AUTOSAR XML (schema 00048)
package /ComponentTypes
  swc implementation Common_GateWay_Implementation: behavior=Common_GateWay_InternalBehavior
    code-descriptors:
      code Default: artifact-descriptors=autosar-engineering-object=category=SWSRC
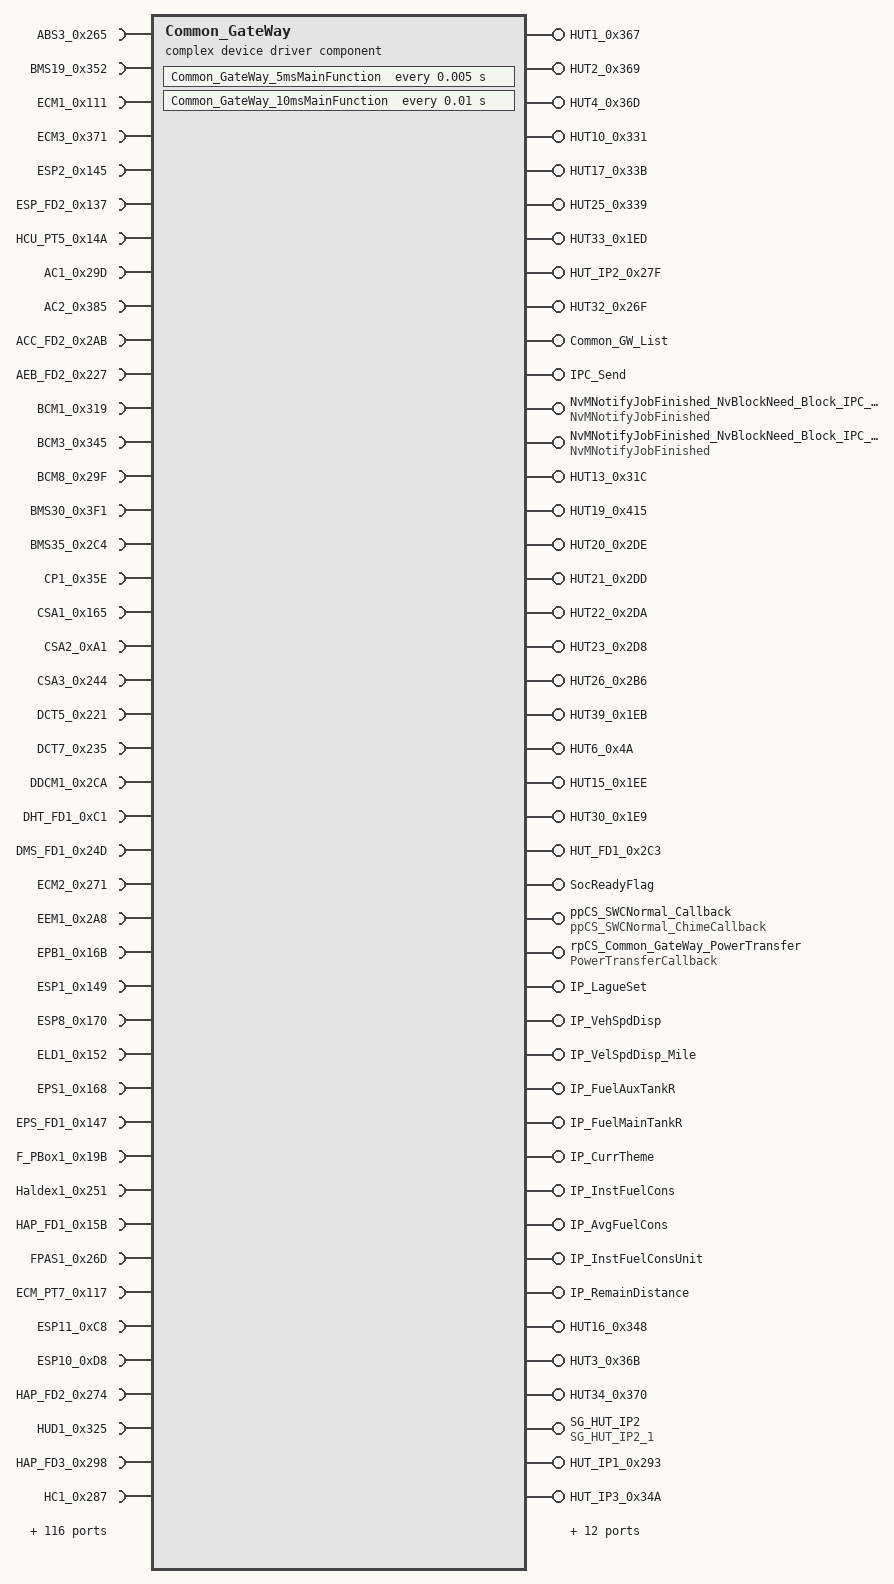
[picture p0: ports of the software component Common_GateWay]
  complex device driver sw component type Common_GateWay
    9 x require port:
      ABS3_0x265: nonqueued-receiver-com-spec{data-element=ABS3_0x265, alive-timeout=0.2, enable-update=true, filter=data-filter-type=ALWAYS, handle-never-received=true, init-value=16 x 0}, required-interface=ABS3_0x265
      BMS19_0x352: nonqueued-receiver-com-spec{data-element=BMS19_0x352, alive-timeout=5, enable-update=true, filter=data-filter-type=ALWAYS, handle-never-received=true, init-value=8 x 0}, required-interface=BMS19_0x352
      ECM1_0x111: nonqueued-receiver-com-spec{data-element=ECM1_0x111, alive-timeout=0.1, enable-update=true, filter=data-filter-type=ALWAYS, handle-never-received=true, init-value=8 x 0}, required-interface=ECM1_0x111
      ECM3_0x371: nonqueued-receiver-com-spec{data-element=ECM3_0x371, alive-timeout=1, enable-update=true, filter=data-filter-type=ALWAYS, handle-never-received=true, init-value=8 x 0}, required-interface=ECM3_0x371
      ESP2_0x145: nonqueued-receiver-com-spec{data-element=ESP2_0x145, alive-timeout=0.2, enable-update=true, filter=data-filter-type=ALWAYS, handle-never-received=true, init-value=16 x 0}, required-interface=ESP2_0x145
      ESP_FD2_0x137: nonqueued-receiver-com-spec{data-element=ESP_FD2_0x137, alive-timeout=0.2, enable-update=true, filter=data-filter-type=ALWAYS, handle-never-received=true, init-value=64 x 0}, required-interface=ESP_FD2_0x137
      HCU_PT5_0x14A: nonqueued-receiver-com-spec{data-element=HCU_PT5_0x14A, alive-timeout=0.2, enable-update=true, filter=data-filter-type=ALWAYS, handle-never-received=true, init-value=8 x 0}, required-interface=HCU_PT5_0x14A
      AC1_0x29D: nonqueued-receiver-com-spec{data-element=AC1_0x29D, alive-timeout=1, enable-update=true, filter=data-filter-type=ALWAYS, handle-never-received=true, init-value=8 x 0}, required-interface=AC1_0x29D
      AC2_0x385: nonqueued-receiver-com-spec{data-element=AC2_0x385, alive-timeout=1, filter=data-filter-type=ALWAYS, handle-never-received=true, init-value=8 x 0}, required-interface=AC2_0x385
    provide port HUT1_0x367: nonqueued-sender-com-spec{data-element=HUT1_0x367, init-value=8 x 0}, provided-interface=HUT1_0x367
    require port ACC_FD2_0x2AB: nonqueued-receiver-com-spec{data-element=ACC_FD2_0x2AB, alive-timeout=1, enable-update=true, filter=data-filter-type=ALWAYS, handle-never-received=true, init-value=64 x 0}, required-interface=ACC_FD2_0x2AB
    provide port HUT2_0x369: nonqueued-sender-com-spec{data-element=HUT2_0x369, init-value=8 x 0}, provided-interface=HUT2_0x369
    39 x require port:
      AEB_FD2_0x227: nonqueued-receiver-com-spec{data-element=AEB_FD2_0x227, alive-timeout=0.5, enable-update=true, filter=data-filter-type=ALWAYS, handle-never-received=true, init-value=64 x 0}, required-interface=AEB_FD2_0x227
      BCM1_0x319: nonqueued-receiver-com-spec{data-element=BCM1_0x319, alive-timeout=0.5, enable-update=true, filter=data-filter-type=ALWAYS, handle-never-received=true, init-value=16 x 0}, required-interface=BCM1_0x319
      BCM3_0x345: nonqueued-receiver-com-spec{data-element=BCM3_0x345, alive-timeout=0.5, enable-update=true, filter=data-filter-type=ALWAYS, handle-never-received=true, init-value=16 x 0}, required-interface=BCM3_0x345
      BCM8_0x29F: nonqueued-receiver-com-spec{data-element=BCM8_0x29F, alive-timeout=1, enable-update=true, filter=data-filter-type=ALWAYS, handle-never-received=true, init-value=8 x 0}, required-interface=BCM8_0x29F
      BMS30_0x3F1: nonqueued-receiver-com-spec{data-element=BMS30_0x3F1, alive-timeout=10, enable-update=true, filter=data-filter-type=ALWAYS, handle-never-received=true, init-value=8 x 0}, required-interface=BMS30_0x3F1
      BMS35_0x2C4: nonqueued-receiver-com-spec{data-element=BMS35_0x2C4, alive-timeout=1, enable-update=true, filter=data-filter-type=ALWAYS, handle-never-received=true, init-value=8 x 0}, required-interface=BMS35_0x2C4
      CP1_0x35E: nonqueued-receiver-com-spec{data-element=CP1_0x35E, alive-timeout=5, enable-update=true, filter=data-filter-type=ALWAYS, handle-never-received=true, init-value=8 x 0}, required-interface=CP1_0x35E
      CSA1_0x165: nonqueued-receiver-com-spec{data-element=CSA1_0x165, alive-timeout=0.2, enable-update=true, filter=data-filter-type=ALWAYS, handle-never-received=true, init-value=8 x 0}, required-interface=CSA1_0x165
      CSA2_0xA1: nonqueued-receiver-com-spec{data-element=CSA2_0xA1, alive-timeout=0.1, enable-update=true, filter=data-filter-type=ALWAYS, handle-never-received=true, init-value=8 x 0}, required-interface=CSA2_0xA1
      CSA3_0x244: nonqueued-receiver-com-spec{data-element=CSA3_0x244, alive-timeout=0.5, enable-update=true, filter=data-filter-type=ALWAYS, handle-never-received=true, init-value=8 x 0}, required-interface=CSA3_0x244
      DCT5_0x221: nonqueued-receiver-com-spec{data-element=DCT5_0x221, alive-timeout=0.2, enable-update=true, filter=data-filter-type=ALWAYS, handle-never-received=true, init-value=8 x 0}, required-interface=DCT5_0x221
      DCT7_0x235: nonqueued-receiver-com-spec{data-element=DCT7_0x235, alive-timeout=0.5, enable-update=true, filter=data-filter-type=ALWAYS, handle-never-received=true, init-value=16 x 0}, required-interface=DCT7_0x235
      DDCM1_0x2CA: nonqueued-receiver-com-spec{data-element=DDCM1_0x2CA, alive-timeout=1, enable-update=true, filter=data-filter-type=ALWAYS, handle-never-received=true, init-value=8 x 0}, required-interface=DDCM1_0x2CA
      DHT_FD1_0xC1: nonqueued-receiver-com-spec{data-element=DHT_FD1_0xC1, alive-timeout=0.1, enable-update=true, filter=data-filter-type=ALWAYS, handle-never-received=true, init-value=64 x 0}, required-interface=DHT_FD1_0xC1
      DMS_FD1_0x24D: nonqueued-receiver-com-spec{data-element=DMS_FD1_0x24D, alive-timeout=0.5, enable-update=true, filter=data-filter-type=ALWAYS, handle-never-received=true, init-value=64 x 0}, required-interface=DMS_FD1_0x24D
      ECM2_0x271: nonqueued-receiver-com-spec{data-element=ECM2_0x271, alive-timeout=0.2, enable-update=true, filter=data-filter-type=ALWAYS, handle-never-received=true, init-value=8 x 0}, required-interface=ECM2_0x271
      EEM1_0x2A8: nonqueued-receiver-com-spec{data-element=EEM1_0x2A8, alive-timeout=1, enable-update=true, filter=data-filter-type=ALWAYS, handle-never-received=true, init-value=8 x 0}, required-interface=EEM1_0x2A8
      EPB1_0x16B: nonqueued-receiver-com-spec{data-element=EPB1_0x16B, alive-timeout=0.2, enable-update=true, filter=data-filter-type=ALWAYS, handle-never-received=true, init-value=8 x 0}, required-interface=EPB1_0x16B
      ESP1_0x149: nonqueued-receiver-com-spec{data-element=ESP1_0x149, alive-timeout=0.2, enable-update=true, filter=data-filter-type=ALWAYS, handle-never-received=true, init-value=16 x 0}, required-interface=ESP1_0x149
      ESP8_0x170: nonqueued-receiver-com-spec{data-element=ESP8_0x170, alive-timeout=0.2, enable-update=true, filter=data-filter-type=ALWAYS, handle-never-received=true, init-value=8 x 0}, required-interface=ESP8_0x170
      ELD1_0x152: nonqueued-receiver-com-spec{data-element=ELD1_0x152, alive-timeout=0.2, enable-update=true, filter=data-filter-type=ALWAYS, handle-never-received=true, init-value=8 x 0}, required-interface=ELD1_0x152
      EPS1_0x168: nonqueued-receiver-com-spec{data-element=EPS1_0x168, alive-timeout=0.2, enable-update=true, filter=data-filter-type=ALWAYS, handle-never-received=true, init-value=8 x 0}, required-interface=EPS1_0x168
      EPS_FD1_0x147: nonqueued-receiver-com-spec{data-element=EPS_FD1_0x147, alive-timeout=0.2, enable-update=true, filter=data-filter-type=ALWAYS, handle-never-received=true, init-value=64 x 0}, required-interface=EPS_FD1_0x147
      F_PBox1_0x19B: nonqueued-receiver-com-spec{data-element=F_PBox1_0x19B, alive-timeout=0.5, enable-update=true, filter=data-filter-type=ALWAYS, handle-never-received=true, init-value=8 x 0}, required-interface=F_PBox1_0x19B
      Haldex1_0x251: nonqueued-receiver-com-spec{data-element=Haldex1_0x251, alive-timeout=0.2, enable-update=true, filter=data-filter-type=ALWAYS, handle-never-received=true, init-value=8 x 0}, required-interface=Haldex1_0x251
      HAP_FD1_0x15B: nonqueued-receiver-com-spec{data-element=HAP_FD1_0x15B, alive-timeout=0.2, enable-update=true, filter=data-filter-type=ALWAYS, handle-never-received=true, init-value=64 x 0}, required-interface=HAP_FD1_0x15B
      FPAS1_0x26D: nonqueued-receiver-com-spec{data-element=FPAS1_0x26D, alive-timeout=1, enable-update=true, filter=data-filter-type=ALWAYS, handle-never-received=true, init-value=8 x 0}, required-interface=FPAS1_0x26D
      ECM_PT7_0x117: nonqueued-receiver-com-spec{data-element=ECM_PT7_0x117, alive-timeout=0.2, enable-update=true, filter=data-filter-type=ALWAYS, handle-never-received=true, init-value=8 x 0}, required-interface=ECM_PT7_0x117
      ESP11_0xC8: nonqueued-receiver-com-spec{data-element=ESP11_0xC8, alive-timeout=0.1, enable-update=true, filter=data-filter-type=ALWAYS, handle-never-received=true, init-value=8 x 0}, required-interface=ESP11_0xC8
      ESP10_0xD8: nonqueued-receiver-com-spec{data-element=ESP10_0xD8, alive-timeout=0.1, enable-update=true, filter=data-filter-type=ALWAYS, handle-never-received=true, init-value=8 x 0}, required-interface=ESP10_0xD8
      HAP_FD2_0x274: nonqueued-receiver-com-spec{data-element=HAP_FD2_0x274, alive-timeout=0.5, enable-update=true, filter=data-filter-type=ALWAYS, handle-never-received=true, init-value=64 x 0}, required-interface=HAP_FD2_0x274
      HUD1_0x325: nonqueued-receiver-com-spec{data-element=HUD1_0x325, alive-timeout=2, enable-update=true, filter=data-filter-type=ALWAYS, handle-never-received=true, init-value=8 x 0}, required-interface=HUD1_0x325
      HAP_FD3_0x298: nonqueued-receiver-com-spec{data-element=HAP_FD3_0x298, alive-timeout=1, enable-update=true, filter=data-filter-type=ALWAYS, handle-never-received=true, init-value=64 x 0}, required-interface=HAP_FD3_0x298
      HC1_0x287: nonqueued-receiver-com-spec{data-element=HC1_0x287, alive-timeout=1, enable-update=true, filter=data-filter-type=ALWAYS, handle-never-received=true, init-value=8 x 0}, required-interface=HC1_0x287
      HCU_HC6_0x314: nonqueued-receiver-com-spec{data-element=HCU_HC6_0x314, alive-timeout=2, enable-update=true, filter=data-filter-type=ALWAYS, handle-never-received=true, init-value=8 x 0}, required-interface=HCU_HC6_0x314
      HCU_HC7_0x3C2: nonqueued-receiver-com-spec{data-element=HCU_HC7_0x3C2, alive-timeout=10, enable-update=true, filter=data-filter-type=ALWAYS, handle-never-received=true, init-value=8 x 0}, required-interface=HCU_HC7_0x3C2
      HCU_PT7_0x248: nonqueued-receiver-com-spec{data-element=HCU_PT7_0x248, alive-timeout=0.5, enable-update=true, filter=data-filter-type=ALWAYS, handle-never-received=true, init-value=8 x 0}, required-interface=HCU_PT7_0x248
      HCU_PT8_0x1C0: nonqueued-receiver-com-spec{data-element=HCU_PT8_0x1C0, alive-timeout=0.5, enable-update=true, filter=data-filter-type=ALWAYS, handle-never-received=true, init-value=8 x 0}, required-interface=HCU_PT8_0x1C0
      HCU_PT4_0x2FA: nonqueued-receiver-com-spec{data-element=HCU_PT4_0x2FA, alive-timeout=1, enable-update=true, filter=data-filter-type=ALWAYS, handle-never-received=true, init-value=8 x 0}, required-interface=HCU_PT4_0x2FA
    6 x provide port:
      HUT4_0x36D: nonqueued-sender-com-spec{data-element=HUT4_0x36D, init-value=8 x 0}, provided-interface=HUT4_0x36D
      HUT10_0x331: nonqueued-sender-com-spec{data-element=HUT10_0x331, init-value=8 x 0}, provided-interface=HUT10_0x331
      HUT17_0x33B: nonqueued-sender-com-spec{data-element=HUT17_0x33B, init-value=8 x 0}, provided-interface=HUT17_0x33B
      HUT25_0x339: nonqueued-sender-com-spec{data-element=HUT25_0x339, init-value=8 x 0}, provided-interface=HUT25_0x339
      HUT33_0x1ED: nonqueued-sender-com-spec{data-element=HUT33_0x1ED, init-value=8 x 0}, provided-interface=HUT33_0x1ED
      HUT_IP2_0x27F: nonqueued-sender-com-spec{data-element=HUT_IP2_0x27F, init-value=16 x 0}, provided-interface=HUT_IP2_0x27F
    18 x require port:
      IFC_FD3_0x2CF: nonqueued-receiver-com-spec{data-element=IFC_FD3_0x2CF, alive-timeout=1, enable-update=true, filter=data-filter-type=ALWAYS, handle-never-received=true, init-value=64 x 0}, required-interface=IFC_FD3_0x2CF
      PEPS2_0x295: nonqueued-receiver-com-spec{data-element=PEPS2_0x295, alive-timeout=0.5, enable-update=true, filter=data-filter-type=ALWAYS, handle-never-received=true, init-value=8 x 0}, required-interface=PEPS2_0x295
      PEPS4_0x302: nonqueued-receiver-com-spec{data-element=PEPS4_0x302, alive-timeout=2, enable-update=true, filter=data-filter-type=ALWAYS, handle-never-received=true, init-value=8 x 0}, required-interface=PEPS4_0x302
      RPAS1_0x26E: nonqueued-receiver-com-spec{data-element=RPAS1_0x26E, alive-timeout=1, enable-update=true, filter=data-filter-type=ALWAYS, handle-never-received=true, init-value=8 x 0}, required-interface=RPAS1_0x26E
      PDCM1_0x2CD: nonqueued-receiver-com-spec{data-element=PDCM1_0x2CD, alive-timeout=1, enable-update=true, filter=data-filter-type=ALWAYS, handle-never-received=true, init-value=8 x 0}, required-interface=PDCM1_0x2CD
      OBC1_0x316: nonqueued-receiver-com-spec{data-element=OBC1_0x316, alive-timeout=2, enable-update=true, filter=data-filter-type=ALWAYS, handle-never-received=true, init-value=8 x 0}, required-interface=OBC1_0x316
      OBC2_0x317: nonqueued-receiver-com-spec{data-element=OBC2_0x317, alive-timeout=2, enable-update=true, filter=data-filter-type=ALWAYS, handle-never-received=true, init-value=8 x 0}, required-interface=OBC2_0x317
      R_PBox1_0x19C: nonqueued-receiver-com-spec{data-element=R_PBox1_0x19C, alive-timeout=0.5, enable-update=true, filter=data-filter-type=ALWAYS, handle-never-received=true, init-value=16 x 0}, required-interface=R_PBox1_0x19C
      T_Box_FD1_0x33: nonqueued-receiver-com-spec{data-element=T_Box_FD1_0x33, enable-update=true, filter=data-filter-type=ALWAYS, handle-never-received=true, init-value=16 x 0}, required-interface=T_Box_FD1_0x33
      T_Box_FD3_0x3E9: nonqueued-receiver-com-spec{data-element=T_Box_FD3_0x3E9, alive-timeout=10, filter=data-filter-type=ALWAYS, init-value=16 x 0}, required-interface=T_Box_FD3_0x3E9
      RSDS_FD1_0x16F: nonqueued-receiver-com-spec{data-element=RSDS_FD1_0x16F, alive-timeout=0.2, enable-update=true, filter=data-filter-type=ALWAYS, handle-never-received=true, init-value=64 x 0}, required-interface=RSDS_FD1_0x16F
      SCM1_0x2D1: nonqueued-receiver-com-spec{data-element=SCM1_0x2D1, alive-timeout=1, enable-update=true, filter=data-filter-type=ALWAYS, handle-never-received=true, init-value=8 x 0}, required-interface=SCM1_0x2D1
      WPC1_0x2BA: nonqueued-receiver-com-spec{data-element=WPC1_0x2BA, alive-timeout=1, enable-update=true, filter=data-filter-type=ALWAYS, handle-never-received=true, init-value=8 x 0}, required-interface=WPC1_0x2BA
      TPMS1_0x341: nonqueued-receiver-com-spec{data-element=TPMS1_0x341, alive-timeout=5, filter=data-filter-type=ALWAYS, handle-never-received=true, init-value=16 x 0}, required-interface=TPMS1_0x341
      TPMS2_0x395: nonqueued-receiver-com-spec{data-element=TPMS2_0x395, alive-timeout=5, enable-update=true, filter=data-filter-type=ALWAYS, handle-never-received=true, init-value=16 x 0}, required-interface=TPMS2_0x395
      Trailer1_0x273: nonqueued-receiver-com-spec{data-element=Trailer1_0x273, alive-timeout=0.5, filter=data-filter-type=ALWAYS, init-value=8 x 0}, required-interface=Trailer1_0x273
      VSG1_0x2E1: nonqueued-receiver-com-spec{data-element=VSG1_0x2E1, alive-timeout=1, enable-update=true, filter=data-filter-type=ALWAYS, handle-never-received=true, init-value=8 x 0}, required-interface=VSG1_0x2E1
      ESCL2_0x303: nonqueued-receiver-com-spec{data-element=ESCL2_0x303, enable-update=true, filter=data-filter-type=ALWAYS, handle-never-received=true, init-value=8 x 0}, required-interface=ESCL2_0x303
    provide port HUT32_0x26F: nonqueued-sender-com-spec{data-element=HUT32_0x26F, init-value=8 x 0}, provided-interface=HUT32_0x26F
    provide port Common_GW_List: provided-com-specs=[{operation=Deinit, queue-length=1}, {operation=Int, queue-length=1}], provided-interface=Common_GW_List
    provide port IPC_Send: server-com-spec{operation=IPC_Send, queue-length=1}, provided-interface=IPC_Send
    10 x require port:
      BMS4_0xF1: nonqueued-receiver-com-spec{data-element=BMS4_0xF1, alive-timeout=0.1, enable-update=true, filter=data-filter-type=ALWAYS, handle-never-received=true, init-value=8 x 0}, required-interface=BMS4_0xF1
      ABM1_0x351: nonqueued-receiver-com-spec{data-element=ABM1_0x351, alive-timeout=5, enable-update=true, filter=data-filter-type=ALWAYS, handle-never-received=true, init-value=16 x 0}, required-interface=ABM1_0x351
      IFC_FD2_0x23D: nonqueued-receiver-com-spec{data-element=IFC_FD2_0x23D, alive-timeout=0.5, enable-update=true, filter=data-filter-type=ALWAYS, handle-never-received=true, init-value=64 x 0}, required-interface=IFC_FD2_0x23D
      IFC_FD5_0x19F: nonqueued-receiver-com-spec{data-element=IFC_FD5_0x19F, alive-timeout=0.5, enable-update=true, filter=data-filter-type=ALWAYS, handle-never-received=true, init-value=64 x 0}, required-interface=IFC_FD5_0x19F
      IFC_FD6_0x222: nonqueued-receiver-com-spec{data-element=IFC_FD6_0x222, alive-timeout=0.5, enable-update=true, filter=data-filter-type=ALWAYS, handle-never-received=true, init-value=64 x 0}, required-interface=IFC_FD6_0x222
      CR_FD1_0x15E: nonqueued-receiver-com-spec{data-element=CR_FD1_0x15E, alive-timeout=0.2, enable-update=true, filter=data-filter-type=ALWAYS, handle-never-received=true, init-value=64 x 0}, required-interface=CR_FD1_0x15E
      EOL_PartNumber_0xF187: nonqueued-receiver-com-spec{data-element=PartNumber_0xF187, filter=data-filter-type=ALWAYS, init-value=13 x 0}, required-interface=EOL_PartNumber_0xF187
      EOL_ReadHardVersion_0xF193: nonqueued-receiver-com-spec{data-element=ReadHardVersion_0xF193, filter=data-filter-type=ALWAYS, init-value=15 x 0}, required-interface=EOL_ReadHardVersion_0xF193
      EOL_ReadSerialNumber_ProductData_0xF18C: nonqueued-receiver-com-spec{data-element=ReadSerialNumber_ProductData_0xF18C, filter=data-filter-type=ALWAYS, init-value=20 x 0}, required-interface=EOL_ReadSerialNumber_ProductData_0xF18C
      EOL_VIPSoftwareVersion_0xFD01: nonqueued-receiver-com-spec{data-element=VIPSoftwareVersion_0xFD01, filter=data-filter-type=ALWAYS, init-value=[0, 0, 0, 0]}, required-interface=EOL_VIPSoftwareVersion_0xFD01
    provide port NvMNotifyJobFinished_NvBlockNeed_Block_IPC_CAN_Data: server-com-spec{operation=JobFinished, queue-length=1}, provided-interface=NvMNotifyJobFinished
    require port NvMService_AC3_Defs_NvBlockNeed_Block_IPC_CAN_Data: required-com-specs=[WriteBlock, RestoreBlockDefaults, ReadBlock, InvalidateNvBlock, GetErrorStatus, EraseBlock], required-interface=NvMService_AC3_Defs
    provide port NvMNotifyJobFinished_NvBlockNeed_Block_IPC_Config_Data: server-com-spec{operation=JobFinished, queue-length=1}, provided-interface=NvMNotifyJobFinished
    9 x require port:
      NvMService_AC3_Defs_NvBlockNeed_Block_IPC_Config_Data: required-com-specs=[WriteBlock, RestoreBlockDefaults, ReadBlock, InvalidateNvBlock, GetErrorStatus, EraseBlock], required-interface=NvMService_AC3_Defs
      AMP2_0x3E3: nonqueued-receiver-com-spec{data-element=AMP2_0x3E3, enable-update=true, filter=data-filter-type=ALWAYS, handle-never-received=true, init-value=16 x 0}, required-interface=AMP2_0x3E3
      AMP3_0x3E5: nonqueued-receiver-com-spec{data-element=AMP3_0x3E5, enable-update=true, filter=data-filter-type=ALWAYS, handle-never-received=true, init-value=8 x 0}, required-interface=AMP3_0x3E5
      BCM12_0x238: nonqueued-receiver-com-spec{data-element=BCM12_0x238, alive-timeout=0.5, enable-update=true, filter=data-filter-type=ALWAYS, handle-never-received=true, init-value=8 x 0}, required-interface=BCM12_0x238
      DSM1_0x2C1: nonqueued-receiver-com-spec{data-element=DSM1_0x2C1, alive-timeout=1, enable-update=true, filter=data-filter-type=ALWAYS, handle-never-received=true, init-value=8 x 0}, required-interface=DSM1_0x2C1
      GW_FD1_0x2BB: nonqueued-receiver-com-spec{data-element=GW_FD1_0x2BB, alive-timeout=1, enable-update=true, filter=data-filter-type=ALWAYS, handle-never-received=true, init-value=64 x 0}, required-interface=GW_FD1_0x2BB
      RPAS2_0x2ED: nonqueued-receiver-com-spec{data-element=RPAS2_0x2ED, alive-timeout=1, enable-update=true, filter=data-filter-type=ALWAYS, handle-never-received=true, init-value=8 x 0}, required-interface=RPAS2_0x2ED
      RSDS_FD2_0x30A: nonqueued-receiver-com-spec{data-element=RSDS_FD2_0x30A, alive-timeout=2, enable-update=true, filter=data-filter-type=ALWAYS, handle-never-received=true, init-value=64 x 0}, required-interface=RSDS_FD2_0x30A
      TMCU_FD3_0x3C9: nonqueued-receiver-com-spec{data-element=TMCU_FD3_0x3C9, alive-timeout=10, enable-update=true, filter=data-filter-type=ALWAYS, handle-never-received=true, init-value=8 x 0}, required-interface=TMCU_FD3_0x3C9
    12 x provide port:
      HUT13_0x31C: nonqueued-sender-com-spec{data-element=HUT13_0x31C, init-value=8 x 0}, provided-interface=HUT13_0x31C
      HUT19_0x415: nonqueued-sender-com-spec{data-element=HUT19_0x415, init-value=8 x 0}, provided-interface=HUT19_0x415
      HUT20_0x2DE: nonqueued-sender-com-spec{data-element=HUT20_0x2DE, init-value=8 x 0}, provided-interface=HUT20_0x2DE
      HUT21_0x2DD: nonqueued-sender-com-spec{data-element=HUT21_0x2DD, init-value=8 x 0}, provided-interface=HUT21_0x2DD
      HUT22_0x2DA: nonqueued-sender-com-spec{data-element=HUT22_0x2DA, init-value=8 x 0}, provided-interface=HUT22_0x2DA
      HUT23_0x2D8: nonqueued-sender-com-spec{data-element=HUT23_0x2D8, init-value=8 x 0}, provided-interface=HUT23_0x2D8
      HUT26_0x2B6: nonqueued-sender-com-spec{data-element=HUT26_0x2B6, init-value=8 x 0}, provided-interface=HUT26_0x2B6
      HUT39_0x1EB: nonqueued-sender-com-spec{data-element=HUT39_0x1EB, init-value=8 x 0}, provided-interface=HUT39_0x1EB
      HUT6_0x4A: nonqueued-sender-com-spec{data-element=HUT6_0x4A, init-value=8 x 0}, provided-interface=HUT6_0x4A
      HUT15_0x1EE: nonqueued-sender-com-spec{data-element=HUT15_0x1EE, init-value=16 x 0}, provided-interface=HUT15_0x1EE
      HUT30_0x1E9: nonqueued-sender-com-spec{data-element=HUT30_0x1E9, init-value=8 x 0}, provided-interface=HUT30_0x1E9
      HUT_FD1_0x2C3: nonqueued-sender-com-spec{data-element=HUT_FD1_0x2C3, init-value=64 x 0}, provided-interface=HUT_FD1_0x2C3
    4 x require port:
      ECM19_0x3B5: nonqueued-receiver-com-spec{data-element=ECM19_0x3B5, alive-timeout=1.2, filter=data-filter-type=ALWAYS, handle-never-received=true, init-value=8 x 0}, required-interface=ECM_VIN
      rpSR_SWCGateWay_Power_Out: nonqueued-receiver-com-spec{data-element=SystemStateOut, alive-timeout=1, filter=data-filter-type=ALWAYS, handle-never-received=true, init-value=constant-reference=PowerOutInit}, required-interface=tiSR_Power_Out
      rpSR_SWCGateWay_Fuel_Set_Module_Data: nonqueued-receiver-com-spec{data-element=Element, filter=data-filter-type=ALWAYS, init-value=fields=[Fuel_Fast_Fill_Status:0, Fuel_Fast_Fill_Status_Aux:0, 0, 0, Fuel_Level_Display_Percent:0, Fuel_Level_Display_Percent_Aux:0, Fuel_Level_Display_Segment:0, Fuel_Warning_Status_Aux:0, Fuel_Warning_Status:0, Fuel_Sensor_Error_Status_Aux:0, Fuel_Sensor_Error_Status:0, Fuel_Level_Display_Value:0, Fuel_Level_Calculate_Value_Aux:0, Fuel_Level_Calculate_Value:0, Fuel_Sensor_Raw_Value_A:0, Fuel_Level_Display_Value_Aux:0, Fuel_Sensor_Raw_Value_B:0, Fuel_Sensor_Switch:0]}, required-interface=tiSR_Fuel_Set_Module_Data
      rpSR_SWCGateWay_TC_Module_Output_Data: nonqueued-receiver-com-spec{data-element=Element, filter=data-filter-type=ALWAYS, init-value=fields=[u16AFE_1st_Display_Output_Data:0, u16AFE_2st_Display_Output_Data:0, u32AFE_1st_Fuel_Trip_Value:0, u32AFE_1st_Fuel_Consumption_Value:0, u32AFE_2st_Fuel_Trip_Value:0, u32AFE_2st_Fuel_Consumption_Value:0, u16IFE_Calculate_Output_Data:0, u16IFE_Display_Output_Data:0, u32IFE_Fuel_Trip_Value:0, u32IFE_Fuel_Consumption_Value:0, u32IFE_Fuel_Consumption_Can_Signal:0, u16AVS_1st_Display_Output_Data:0, u16AVS_2st_Display_Output_Data:0, u32AVS_1st_Driving_Time_Value:0, u32AVS_2st_Driving_Time_Value:0, u32AVS_1st_Fuel_Trip_Value:0, u32AVS_2st_Fuel_Trip_Value:0, u8DrivingTime_1st_Display_Hour:0, u8DrivingTime_2st_Display_Hour:0, u8DrivingTime_1st_Display_Minute:0, u8DrivingTime_2st_Display_Minute:0, u16DTE_Fuel_Tank_Volume:0, u16DTE_Fuel_Tank_Volume_Aux:0, u8DTE_Fuel_Stage_Consumption:0, u8DTE_Fuel_Stage_Consumption_Aux:0, u16DTE_Display_Output_Data:0, u16DTE_Display_Output_Data_Aux:0, u16DTE_Calculate_Output_Data:0, u16SFC_Output_Data:0, u8IFC_Poc_Update:0, u16IFC_Poc_Calculate_Value:0, u16SFC_For_Fuel_Output_Data:0, u16IFC_Poc_For_Fuel_Calculate_Rate:0, u16IFC_Poc_For_Fuel_Calculate_Rate_Aux:0]}, required-interface=tiSR_TC_Module_Output_Data
    provide port SocReadyFlag: nonqueued-sender-com-spec{data-element=Element, init-value=0}, provided-interface=SocReadyFlag
    provide port ppCS_SWCNormal_Callback: server-com-spec{operation=Operation, queue-length=1}, provided-interface=ppCS_SWCNormal_ChimeCallback
    7 x require port:
      rcCS_SWCNormal_ChimeCallback: client-com-spec=Operation, required-interface=tiCS_SWCNormal_ChimeCallback
      rcCS_SWCNormal_TTCallback: client-com-spec=Operation, required-interface=tiCS_SWCNormal_TTCallback
      rcCS_SWCNormal_WrnCallback: client-com-spec=Operation, required-interface=tiCS_SWCNormal_WrnCallback
      rpCS_AppClearDTCInfo: client-com-spec=AppClearDTCInfo, required-interface=PpCS_AppClearDTCInfo
      rpCS_AppReadDtcInfomation: client-com-spec=AppReadDtcInformation, required-interface=PpCS_AppReadDtcInfomation
      Rc_CanOutputViaGateway: required-interface=SafetyCanOutputViaNormal
        required-com-specs:
          data-element=RollingCounter_IP2, filter=data-filter-type=ALWAYS, init-value=0
          data-element=IP_VINcompr, filter=data-filter-type=ALWAYS, init-value=0
          data-element=IP_VehTotDistanceValid, filter=data-filter-type=ALWAYS, init-value=0
          data-element=IP_VehTotDistance, filter=data-filter-type=ALWAYS, init-value=16777215
          data-element=IP_PassSeatBeltWarnLmpFailSts, filter=data-filter-type=ALWAYS, init-value=0
          data-element=IP_VehSpdUnit, filter=data-filter-type=ALWAYS, init-value=0
          data-element=IP_FuelLvlInfo, filter=data-filter-type=ALWAYS, init-value=255
          data-element=IP_FuelLvlLowLmpSts, filter=data-filter-type=ALWAYS, init-value=0
          data-element=IP_Err, filter=data-filter-type=ALWAYS, init-value=0
          data-element=IP_EngOilPressLowLmpSts, filter=data-filter-type=ALWAYS, init-value=0
          data-element=IP_DrvSeatBeltWarnLmpFailSts, filter=data-filter-type=ALWAYS, init-value=0
          data-element=IP_BattChrgLmpSts, filter=data-filter-type=ALWAYS, init-value=0
          data-element=IP_ACCErr, filter=data-filter-type=ALWAYS, init-value=0
          data-element=IP_ABMWarnLmpFailrSts, filter=data-filter-type=ALWAYS, init-value=0
          data-element=dummy_HUT_IP2_0, filter=data-filter-type=ALWAYS, init-value=0
          data-element=CheckSum_IP2, filter=data-filter-type=ALWAYS, init-value=0
          data-element=IP_RemainDistance, filter=data-filter-type=ALWAYS, init-value=4095
          data-element=IP_InstFuelConsUnit, filter=data-filter-type=ALWAYS, init-value=0
          data-element=IP_AvgFuelCons, filter=data-filter-type=ALWAYS, init-value=4095
          data-element=IP_InstFuelCons, filter=data-filter-type=ALWAYS, init-value=16383
          data-element=IP_CurrTheme, filter=data-filter-type=ALWAYS, init-value=4
          data-element=IP_VehSpdDisp, filter=data-filter-type=ALWAYS, init-value=0
          data-element=IP_FuelMainTankR, filter=data-filter-type=ALWAYS, init-value=10
          data-element=IP_FuelAuxTankR, filter=data-filter-type=ALWAYS, init-value=10
          data-element=IP_VelSpdDisp_Mile, filter=data-filter-type=ALWAYS, init-value=0
          data-element=IP_LagueSet, filter=data-filter-type=ALWAYS, init-value=15
          data-element=IP_EBDFailSts, filter=data-filter-type=ALWAYS, init-value=0
      CNA_SignalSet: client-com-spec=Operation, required-interface=CNA_SignalSet
    provide port rpCS_Common_GateWay_PowerTransfer: provided-com-specs=[{operation=Standby2NomalCallback, queue-length=1}, {operation=Nomal2StandbyCallback, queue-length=1}], provided-interface=PowerTransferCallback
    require port rcCS_SWCNormal_HMIResetTC: client-com-spec=Callback, required-interface=tiCS_HMIResetTC
    require port rcCS_SWCNormal_ReceiveMenuSetting: client-com-spec=Callback, required-interface=tiCS_ReceiveMenuSetting
    10 x provide port:
      IP_LagueSet: nonqueued-sender-com-spec{data-element=IP_LagueSet, init-value=0}, provided-interface=IP_LagueSet
      IP_VehSpdDisp: nonqueued-sender-com-spec{data-element=IP_VehSpdDisp, init-value=0}, provided-interface=IP_VehSpdDisp
      IP_VelSpdDisp_Mile: nonqueued-sender-com-spec{data-element=IP_VelSpdDisp_Mile, init-value=0}, provided-interface=IP_VelSpdDisp_Mile
      IP_FuelAuxTankR: nonqueued-sender-com-spec{data-element=IP_FuelAuxTankR, init-value=0}, provided-interface=IP_FuelAuxTankR
      IP_FuelMainTankR: nonqueued-sender-com-spec{data-element=IP_FuelMainTankR, init-value=0}, provided-interface=IP_FuelMainTankR
      IP_CurrTheme: nonqueued-sender-com-spec{data-element=IP_CurrTheme, init-value=0}, provided-interface=IP_CurrTheme
      IP_InstFuelCons: nonqueued-sender-com-spec{data-element=IP_InstFuelCons, init-value=0}, provided-interface=IP_InstFuelCons
      IP_AvgFuelCons: nonqueued-sender-com-spec{data-element=IP_AvgFuelCons, init-value=0}, provided-interface=IP_AvgFuelCons
      IP_InstFuelConsUnit: nonqueued-sender-com-spec{data-element=IP_InstFuelConsUnit, init-value=0}, provided-interface=IP_InstFuelConsUnit
      IP_RemainDistance: nonqueued-sender-com-spec{data-element=IP_RemainDistance, init-value=0}, provided-interface=IP_RemainDistance
    5 x require port:
      ABS1_0x231: nonqueued-receiver-com-spec{data-element=ABS1_0x231, alive-timeout=0.2, enable-update=true, filter=data-filter-type=ALWAYS, handle-never-received=true, init-value=8 x 0}, required-interface=ABS1_0x231
      ABS2_0x246: nonqueued-receiver-com-spec{data-element=ABS2_0x246, alive-timeout=0.2, enable-update=true, filter=data-filter-type=ALWAYS, handle-never-received=true, init-value=8 x 0}, required-interface=ABS2_0x246
      ACC_FD3_0x2B4: nonqueued-receiver-com-spec{data-element=ACC_FD3_0x2B4, alive-timeout=1, enable-update=true, filter=data-filter-type=ALWAYS, handle-never-received=true, init-value=64 x 0}, required-interface=ACC_FD3_0x2B4
      BCM6_0x28C: nonqueued-receiver-com-spec{data-element=BCM6_0x28C, alive-timeout=1, enable-update=true, filter=data-filter-type=ALWAYS, handle-never-received=true, init-value=8 x 0}, required-interface=BCM6_0x28C
      PLG_1_0x2FE: nonqueued-receiver-com-spec{data-element=PLG_1_0x2FE, alive-timeout=1, enable-update=true, filter=data-filter-type=ALWAYS, handle-never-received=true, init-value=8 x 0}, required-interface=PLG_1_0x2FE
    4 x provide port:
      HUT16_0x348: nonqueued-sender-com-spec{data-element=HUT16_0x348, init-value=8 x 0}, provided-interface=HUT16_0x348
      HUT3_0x36B: nonqueued-sender-com-spec{data-element=HUT3_0x36B, init-value=8 x 0}, provided-interface=HUT3_0x36B
      HUT34_0x370: nonqueued-sender-com-spec{data-element=HUT34_0x370, init-value=8 x 0}, provided-interface=HUT34_0x370
      SG_HUT_IP2: nonqueued-sender-com-spec{data-element=SG_HUT_IP2, uses-end-to-end-protection=true, init-value=fields=[CheckSum_IP2:0, IP_ABMWarnLmpFailrSts:0, IP_ACCErr:0, IP_BattChrgLmpSts:0, IP_DrvSeatBeltWarnLmpFailSts:0, IP_EngOilPressLowLmpSts:0, IP_Err:0, IP_FuelLvlInfo:0, IP_FuelLvlLowLmpSts:0, IP_PassSeatBeltWarnLmpFailSts:0, IP_VehSpdUnit:0, IP_VehTotDistance:0, IP_VehTotDistanceValid:0, IP_VINcompr:0, RollingCounter_IP2:0]}, provided-interface=SG_HUT_IP2_1
    require port rpSR_SWCGateWay_DtcInfoForIPErrorStatus: nonqueued-receiver-com-spec{data-element=Element, filter=data-filter-type=ALWAYS, init-value=0}, required-interface=tiSR_DtcInfoForIPErrorStatus
    require port rpCS_SWCGateWay_GetVinNumber: client-com-spec=Operation, required-interface=tiCS_GetVinNumber
    provide port HUT_IP1_0x293: nonqueued-sender-com-spec{data-element=HUT_IP1_0x293, init-value=8 x 0}, provided-interface=HUT_IP1_0x293
    provide port HUT_IP3_0x34A: nonqueued-sender-com-spec{data-element=HUT_IP3_0x34A, init-value=16 x 0}, provided-interface=HUT_IP3_0x34A
    11 x require port:
      Rc_CanOutout_IP_EBDFailSts: nonqueued-receiver-com-spec{data-element=IP_EBDFailSts, filter=data-filter-type=ALWAYS, init-value=0}, required-interface=IP_EBDFailSts
      ComM_UserRequest: required-com-specs=[GetRequestedComMode, GetMaxComMode, GetCurrentComMode, RequestComMode], required-interface=ComM_UserRequest
      SG_ACC7_ACC_FD2: nonqueued-receiver-com-spec{data-element=SG_ACC7_ACC_FD2, uses-end-to-end-protection=true, alive-timeout=1, enable-update=true, handle-never-received=true, init-value=fields=[ACC_LeTargrtDection:0, ACC_LeTgtDx:0, ACC_LeTgtDy:0, ACC_LeTgtTyp:0, ACC_RiTargrtDetn:0, ACC_RiTgtDx:0, ACC_RiTgtDy:0, ACC_RiTgtTyp:0, Checksum_ACC7:0, dummy_ACC_FD2_19:0, dummy_ACC_FD2_20:0, Request_driveoff:0, RollingCounter_ACC7:0]}, required-interface=SG_ACC7_ACC_FD2
      Cconfig_KindBuffers_400Bytes: nonqueued-receiver-com-spec{data-element=CconfigKind_400Bytes, filter=data-filter-type=ALWAYS, init-value=400 x 0}, required-interface=Cconfig_KindBuffers_400Bytes
      rpCS_SWCGateWay_ReceiveSafetyGearCRC: client-com-spec=Callback, required-interface=tiCS_ReceiveSafetyGearCRC
      rpCS_SWCGateWay_ReceiveSafetyTTCRC: client-com-spec=Callback, required-interface=tiCS_ReceiveSafetyTTCRC
      rcCS_SWCGateWay_ReceiveSafetyGearCRC: client-com-spec=Callback, required-interface=tiCS_ReceiveSafetyGearCRC
      rcCS_SWCGateWay_ReceiveSafetyTTCRC: client-com-spec=Callback, required-interface=tiCS_ReceiveSafetyTTCRC
      rpCS_GetVehicleModeInfo: client-com-spec=Data, required-interface=piCS_GetVehicleModeInfo
      rpCS_GetCANMatrixVersionInfo: client-com-spec=Data, required-interface=piCS_GetCANMatrixVersionInfo
      piSR_E2ESwitchChangeTrigger: nonqueued-receiver-com-spec{data-element=Element, filter=data-filter-type=ALWAYS, init-value=0}, required-interface=piSR_E2ESwitchChangeTrigger
    provide port ppCS_SWCGateWay_IPC_TransmitSignal: server-com-spec{operation=Callback, queue-length=1}, provided-interface=tiCS_IPC_TransmitSignal
    provide port ppCS_SWCGateWay_IPC_Tx_E2E_CanMsg_HUT_IP2: server-com-spec{operation=Callback, queue-length=1}, provided-interface=tiCS_IPC_Tx_E2E_CanMsg_HUT_IP2
    require port DCT3_0xA6: nonqueued-receiver-com-spec{data-element=DCT3_0xA6, alive-timeout=0.1, enable-update=true, handle-never-received=true, init-value=8 x 0}, required-interface=DCT3_0xA6
    require port ECM11_0x2D3: nonqueued-receiver-com-spec{data-element=ECM11_0x2D3, alive-timeout=1, enable-update=true, handle-never-received=true, init-value=8 x 0}, required-interface=ECM11_0x2D3
    require port rpSR_SWCGateWay_MenuSetData: nonqueued-receiver-com-spec{data-element=Element, filter=data-filter-type=ALWAYS, init-value=fields=[NaviLimitSpeed:0, OverSpeedEnable:0, Language:0, ClusterTheme:0, OdometerUnit:0, TemperatureUnit:0, TirePressureUnit:0, TripComputerId:0, InteractiveCarId:0, DrivingModeMemorySwitch:0, TimeUnit:0, HighwayAssistSwitch:0, LaneChangeAssistSwitch:0, Cluster_Sunrise_Sunset_Mode:0, Cluster_Auto_Mode:0, DrvgModeMemReq:0, DrvingModReq_HUT:0, DataSyncFlag:0, AtmosphereLampLinkageSwt_Sts:0, SimSoundWaveLinkageSwt_Sts:0]}, required-interface=tiSR_MenuSetData
    provide port ppCS_SWCGateWay_IPC_API_SetEventTxSignalBuffer: server-com-spec{operation=Operation, queue-length=1}, provided-interface=tiCS_IPC_API_SetEventTxSignalBuffer
    require port rpCS_SWCSafety_TTCallback: client-com-spec=Operation, required-interface=tiCS_SWCSafety_TTCallback
    provide port SG_HUT32: nonqueued-sender-com-spec{data-element=SG_HUT32, uses-end-to-end-protection=true, init-value=fields=[CheckSum_HUT32:0, ContnPrkgReq:0, ContnPrkgReqValid:0, DetVideoLost:0, PrkgCtrlModReq:0, PrkgCtrlModReqValid:0, PrkStraightContinueReq_HUT:0, PrkStraightModSel_HUT:0, PrkStraightStrtReq_HUT:0, PrkStraightSts_HUT:0, PrkStraightSuspendOrFinishReq_HUT:0, PrkStraightSwtReq_HUT:0, PrkStraightVehStrtReq_HUT_Valid:0, RollingCounter_HUT32:0, ScrnOpSts:0, VolLampDispSts:0, XLvl:2047, YLvl:2047]}, provided-interface=SG_HUT32
    provide port ppCS_SWCGateWay_IPC_Tx_E2E_CanMsg_HUT32: server-com-spec{operation=CallBack, queue-length=1}, provided-interface=tiCS_IPC_Tx_E2E_CanMsg_HUT32
    6 x require port:
      IPC_DataSend_If: client-com-spec=Operation, required-interface=IPC_DataSend_If
      rpCS_SWCGateWay_E2ESwitchStatusRead: client-com-spec=Operation, required-interface=tiCS_E2EAndSecocCommonPort
      rpCS_SWCGateWay_E2ESwitchStatusWrite: client-com-spec=Operation, required-interface=tiCS_E2EAndSecocCommonPort
      rpCS_SWCGateWay_SecOcSwitchStatusRead: client-com-spec=Operation, required-interface=tiCS_E2EAndSecocCommonPort
      rpCS_SWCGateWay_SecOcSwitchStatusWrite: client-com-spec=Operation, required-interface=tiCS_E2EAndSecocCommonPort
      ACC_FD4_0x2B8: nonqueued-receiver-com-spec{data-element=ACC_FD4_0x2B8, alive-timeout=1, enable-update=true, filter=data-filter-type=ALWAYS, handle-never-received=true, init-value=64 x 0}, required-interface=ACC_FD4_0x2B8
    provide port ppSR_SWCGateWay_S2M_Information: provided-com-specs=[{data-element=TachoValue, init-value=0}, {data-element=SpeedValue, init-value=0}], provided-interface=tiSR_S2M_Information
    4 x require port:
      SG_ACC6_ACC_FD2: nonqueued-receiver-com-spec{data-element=SG_ACC6_ACC_FD2, uses-end-to-end-protection=true, alive-timeout=1, enable-update=true, filter=data-filter-type=ALWAYS, handle-never-received=true, init-value=fields=[ACC_EgoStatus:0, ACC_PotentialTgtDetn:0, ACC_PotentialTgtDx:0, ACC_PotentialTgtDy:0, ACC_PotentialTgtTyp:0, ACC_RlvTgtDetn:0, ACC_RlvTgtDx:0, ACC_RlvTgtDy:0, ACC_RlvTgtTyp:0, Checksum_ACC6:0, dummy_ACC_FD2_16:0, dummy_ACC_FD2_17:0, dummy_ACC_FD2_18:0, RollingCounter_ACC6:0]}, required-interface=SG_ACC6_ACC_FD2
      SG_ACC8_ACC_FD2: nonqueued-receiver-com-spec{data-element=SG_ACC8_ACC_FD2, uses-end-to-end-protection=true, alive-timeout=1, enable-update=true, handle-never-received=true, init-value=fields=[ADAS_DriverInloop_Monitor:0, Checksum_ACC8:0, HWA_InterSysInfoDisp:0, HWA_LaneChange:0, HWA_LaneChangeReq:0, HWA_ModDisp:0, HWA_warning:0, Longctrl_HCUTrqReq_DVR:0, RollingCounter_ACC8:0, dummy_ACC_FD2_11:0, dummy_ACC_FD2_12:0, dummy_ACC_FD2_13:0, dummy_ACC_FD2_14:0, dummy_ACC_FD2_15:0]}, required-interface=SG_ACC8_ACC_FD2
      SG_ACC3_ACC_FD2: nonqueued-receiver-com-spec{data-element=SG_ACC3_ACC_FD2, uses-end-to-end-protection=true, alive-timeout=1, enable-update=true, handle-never-received=true, init-value=fields=[ALC_InterSysInfoDisp:0, ALC_Resp:0, Checksum_ACC3:0, HWA_Resp:0, HWA_SnvtySet_Resp:0, ICA_HandsOffResp:0, ISL_Resp:0, Longctrl_Decel_Req_DVR:0, Longctrl_Decel_ReqValue_DVR:0, Longctrl_DecelToStopReq_DVR:0, Longctrl_DrvOFF_Req_DVR:0, Longctrl_EngTrqReq_DVR:32767, Longctrl_EngTrqReqActive_DVR:0, Longctrl_HCUTrqReqActive_DVR:0, Longctrl_ModSts_DVR:0, Longctrl_ParkShiftReq_DVR:0, Longctrl_VehHldReq_DVR:0, RollingCounter_ACC3:0, dummy_ACC_FD2_4:0, dummy_ACC_FD2_5:0, dummy_ACC_FD2_6:0, dummy_ACC_FD2_7:0]}, required-interface=SG_ACC3_ACC_FD2
      SG_ACC4_ACC_FD2: nonqueued-receiver-com-spec{data-element=SG_ACC4_ACC_FD2, uses-end-to-end-protection=true, alive-timeout=1, enable-update=true, handle-never-received=true, init-value=fields=[ACC_FctSts:0, ACC_InterSysInfoDisp:0, ACC_ModDisp:0, ACC_ObjDetecte:0, ACC_SpdSetValue:0, ACC_TakeOverReq:0, ACC_TgtObjBarDisp:0, ACC_TimeGapSet:0, Checksum_ACC4:0, ISL_InterSysInfoDisp:0, RollingCounter_ACC4:0, TJA_ACC_SelSts:0, TJA_ICA_InterSysInfoDisp:0, TJA_ICA_ModDisp:0, CruCha_ModDisp:0, CruChar_InterSysInfoDisp:0, Longctrl_HazActv:0, dummy_ACC_FD2_8:0, dummy_ACC_FD2_9:0, dummy_ACC_FD2_10:0]}, required-interface=SG_ACC4_ACC_FD2
    provide port HUT35_0x1E5: nonqueued-sender-com-spec{data-element=HUT35_0x1E5, init-value=8 x 0}, provided-interface=HUT35_0x1E5
    provide port HUT_FD4_0x1DA: nonqueued-sender-com-spec{data-element=HUT_FD4_0x1DA, init-value=64 x 0}, provided-interface=HUT_FD4_0x1DA
    require port HAP_FD6_0x289: nonqueued-receiver-com-spec{data-element=HAP_FD6_0x289, uses-end-to-end-protection=true, alive-timeout=1, enable-update=true, filter=data-filter-type=ALWAYS, handle-never-received=true, init-value=64 x 0}, required-interface=HAP_FD6_0x289
    provide port HUT40_0x2CE: nonqueued-sender-com-spec{data-element=HUT40_0x2CE, init-value=8 x 0}, provided-interface=HUT40_0x2CE
    14 x require port:
      HCM_R1_0x30D: nonqueued-receiver-com-spec{data-element=HCM_R1_0x30D, alive-timeout=2, enable-update=true, filter=data-filter-type=ALWAYS, handle-never-received=true, init-value=8 x 0}, required-interface=HCM_R1_0x30D
      HCM_L1_0x308: nonqueued-receiver-com-spec{data-element=HCM_L1_0x308, alive-timeout=2, enable-update=true, filter=data-filter-type=ALWAYS, handle-never-received=true, init-value=8 x 0}, required-interface=HCM_L1_0x308
      HAP_FD7_0x29B: nonqueued-receiver-com-spec{data-element=HAP_FD7_0x29B, alive-timeout=1, enable-update=true, filter=data-filter-type=ALWAYS, handle-never-received=true, init-value=64 x 0}, required-interface=HAP_FD7_0x29B
      BMS8_0x285: nonqueued-receiver-com-spec{data-element=BMS8_0x285, alive-timeout=1, enable-update=true, filter=data-filter-type=ALWAYS, handle-never-received=true, init-value=8 x 0}, required-interface=BMS8_0x285
      BMS22_0x3BF: nonqueued-receiver-com-spec{data-element=BMS22_0x3BF, alive-timeout=10, enable-update=true, filter=data-filter-type=ALWAYS, handle-never-received=true, init-value=8 x 0}, required-interface=BMS22_0x3BF
      BMS_FD14_0x1E3: nonqueued-receiver-com-spec{data-element=BMS_FD14_0x1E3, init-value=8 x 0}, required-interface=BMS_FD14_0x1E3
      HCU_HC8_0x1E2: nonqueued-receiver-com-spec{data-element=HCU_HC8_0x1E2, filter=data-filter-type=ALWAYS, init-value=8 x 0}, required-interface=HCU_HC8_0x1E2
      HCU_HC3_0x268: nonqueued-receiver-com-spec{data-element=HCU_HC3_0x268, alive-timeout=0.5, enable-update=true, filter=data-filter-type=ALWAYS, handle-never-received=true, init-value=8 x 0}, required-interface=HCU_HC3_0x268
      HCU_FD1_0x60: nonqueued-receiver-com-spec{data-element=HCU_FD1_0x60, alive-timeout=0.1, enable-update=true, filter=data-filter-type=ALWAYS, handle-never-received=true, init-value=64 x 0}, required-interface=HCU_FD1_0x60
      rpCS_SWCGateWay_TC_EnergyInfo: client-com-spec=Operation, required-interface=tiCS_TC_EnergyInfo
      rpCS_SWCGateWay_TC_EnergyInfoResp: client-com-spec=Operation, required-interface=tiCS_TC_EnergyInfoResp
      HCU_HP5_0x201: nonqueued-receiver-com-spec{data-element=HCU_HP5_0x201, alive-timeout=0.5, enable-update=true, filter=data-filter-type=ALWAYS, handle-never-received=true, init-value=8 x 0}, required-interface=HCU_HP5_0x201
      HCU_HP6_0x11A: nonqueued-receiver-com-spec{data-element=HCU_HP6_0x11A, alive-timeout=0.2, enable-update=true, filter=data-filter-type=ALWAYS, handle-never-received=true, init-value=8 x 0}, required-interface=HCU_HP6_0x11A
      rpCS_SWCGateWay_ComEx: required-com-specs=[SendSignal, ReceiveSignal, GetRxE2EStatus], required-interface=ComEx
    provide port ppSR_SWCGateWay_EnergyInfoId: nonqueued-sender-com-spec{data-element=Data, init-value=fields=[ModuleId:0, ClientId:0]}, provided-interface=tiSR_EnergyInfoId
    8 x require port:
      rpCS_SWCGateWay_AdasStatus: client-com-spec=Callback, required-interface=tiCS_HMIResetTC
      rpCS_SWCGateWay_ReceiveHMIPowerMode: client-com-spec=Callback, required-interface=tiCS_HMIResetTC
      rpCS_SWCGateway_UTCTime: required-com-specs=[UTC2PerpetualCalendar, GetUTCTimeInMillis], required-interface=IRTC_Service
      rpSR_SWCGateWay_ReceiveRTCTime: required-interface=if_RTC
        required-com-specs:
          data-element=SleepDateTime, filter=data-filter-type=ALWAYS, init-value=-1
          data-element=UtcTime, filter=data-filter-type=ALWAYS, init-value=-1
      rpCS_SWCGateWay_CNA_SignalSetNoTrigger: client-com-spec=Operation, required-interface=CNA_SignalSetNoTrigger
      rpCS_SWCGateWay_ReceiveMenuTheme: client-com-spec=Callback, required-interface=tiCS_ReceiveMenuSetting
      rpCS_SWCGateWay_CNA_SignalSet_U8N: client-com-spec=Operation, required-interface=CNA_SignalSet_U8N
      rpCS_SWCGateWay_TtToChime: client-com-spec=Callback, required-interface=TtToChime
    provide port AWakeHold: nonqueued-sender-com-spec{data-element=DVRRemtCnSts, init-value=0}, provided-interface=AWakeHold
    provide port AwakeHlod_Heartbeat: nonqueued-sender-com-spec{data-element=counter, init-value=0}, provided-interface=AwakeHlod_Heartbeat
    5 x require port:
      CNA_SignalGroupSet: client-com-spec=Operation, required-interface=CNA_SignalGroupSet
      Vconfig_GetKindBuffers: nonqueued-receiver-com-spec{data-element=AllKinds, filter=data-filter-type=ALWAYS, init-value=600 x 0}, required-interface=Vconfig_GetKindBuffers
      VConfig_GetKindConfig: client-com-spec=Operation_VConfig_GetKindConfig, required-interface=VConfig_GetKindConfig
      rcCS_SWCNormal_ReceiveOffroadInfo: client-com-spec=Callback, required-interface=tiCS_ReceiveOffroadInfo
      rpSR_SWCGateWay_CanOutput_IP_ABMWarnLmpFailrSts: nonqueued-receiver-com-spec{data-element=Element, filter=data-filter-type=ALWAYS, init-value=0}, required-interface=tiSR_CanOutput_IP_ABMWarnLmpFailrSts
    behavior Common_GateWay_InternalBehavior
      exclusive area ExclusiveArea
      ar-typed-per-instance-memorys:
        data NvBlockNeed_Block_IPC_Config_Data_MirrorBlock: sw-calibration-access=READ-ONLY, type=IPC_Config_Type
        data NvBlockNeed_Block_IPC_CAN_Data_MirrorBlock: sw-calibration-access=READ-ONLY, type=NVM_IPC_CAN_Type
      init event SWC_CAN_InitEvent: start-on-event=Common_GateWay_Init
      timing event TMT_SWC_CAN_MainFunction: start-on-event=Common_GateWay_5msMainFunction, period=0.005
      12 x operation invoked event:
        OIT_Common_GW_List_Deinit_Common_GW_List_Deinit: start-on-event=Common_GW_List_Deinit, operation=Common_GW_List.Deinit
        OIT_Common_GW_List_Int_Common_GW_List_Int: start-on-event=Common_GW_List_Int, operation=Common_GW_List.Int
        OIT_IPC_Send_IPC_Send_IPC_Send_IPC_Send: start-on-event=IPC_Send_IPC_Send, operation=IPC_Send.IPC_Send
        OIT_NvMNotifyJobFinished_NvBlockNeed_Block_IPC_Config_Data_JobFinished_NvMNotifyJobFinished_NvBlockNeed_Block_IPC_Config4606C687: start-on-event=NvMNotifyJobFinished_NvBlockNeed_Block_IPC_Config_Data_JobFinished, operation=NvMNotifyJobFinished_NvBlockNeed_Block_IPC_Config_Data.JobFinished
        OIT_NvMNotifyJobFinished_NvBlockNeed_Block_IPC_CAN_Data_JobFinished_NvMNotifyJobFinished_NvBlockNeed_Block_IPC_CAN_Data_A0442867: start-on-event=NvMNotifyJobFinished_NvBlockNeed_Block_IPC_CAN_Data_JobFinished, operation=NvMNotifyJobFinished_NvBlockNeed_Block_IPC_CAN_Data.JobFinished
        OIT_ppCS_SWCNormal_Callback_Operation_ppCS_SWCNormal_Callback_Operation: start-on-event=ppCS_SWCNormal_Callback_Operation, operation=ppCS_SWCNormal_Callback.Operation
        OIT_Common_GateWay_Standby2Nomal_rpCS_Common_GateWay_PowerTransfer_Standby2NomalCallback: start-on-event=Common_GateWay_Standby2Nomal_Callbcak, operation=rpCS_Common_GateWay_PowerTransfer.Standby2NomalCallback
        OIT_Common_GateWay_Nomal2Standby_Callbcak_rpCS_Common_GateWay_PowerTransfer_Nomal2StandbyCallback: start-on-event=Common_GateWay_Nomal2Standby_Callbcak, operation=rpCS_Common_GateWay_PowerTransfer.Nomal2StandbyCallback
        OIT_ppCS_SWCGateWay_IPC_Tx_E2E_CanMsg_HUT_IP2_Callback_ppCS_SWCGateWay_IPC_Tx_E2E_CanMsg_HUT_IP2_Callback: start-on-event=IPC_Tx_E2E_CanMsg_HUT_IP2_Callback, operation=ppCS_SWCGateWay_IPC_Tx_E2E_CanMsg_HUT_IP2.Callback
        OIT_ppCS_SWCGateWay_IPC_TransmitSignal_Callback_ppCS_SWCGateWay_IPC_TransmitSignal_Callback: start-on-event=IPC_TransmitSignal_Callback, operation=ppCS_SWCGateWay_IPC_TransmitSignal.Callback
        OIT_ppCS_SWCGateWay_IPC_API_SetEventTxSignalBuffer_Operation_ppCS_SWCGateWay_IPC_API_SetEventTxSignalBuffer_Operation: start-on-event=IPC_API_SetEventTxSignalBuffer_Operation, operation=ppCS_SWCGateWay_IPC_API_SetEventTxSignalBuffer.Operation
        OIT_ppCS_SWCGateWay_IPC_Tx_E2E_CanMsg_HUT32_CallBack_ppCS_SWCGateWay_IPC_Tx_E2E_CanMsg_HUT32_CallBack: start-on-event=IPC_Tx_E2E_CanMsg_HUT32_CallBack, operation=ppCS_SWCGateWay_IPC_Tx_E2E_CanMsg_HUT32.CallBack
      timing event TMT_Common_GateWay_10msMainFunction: start-on-event=Common_GateWay_10msMainFunction, period=0.01
      port-api-options:
        enable-take-address=true, error-handling=NO-TRANSFORMER-ERROR-HANDLING, indirect-api=false, port=Common_GW_List
        enable-take-address=true, error-handling=NO-TRANSFORMER-ERROR-HANDLING, indirect-api=false, port=rpCS_SWCGateWay_AdasStatus
        enable-take-address=true, error-handling=NO-TRANSFORMER-ERROR-HANDLING, indirect-api=false, port=rpCS_SWCGateWay_ReceiveHMIPowerMode
        enable-take-address=true, error-handling=NO-TRANSFORMER-ERROR-HANDLING, indirect-api=false, port=rpCS_SWCGateWay_ReceiveMenuTheme
        enable-take-address=true, error-handling=NO-TRANSFORMER-ERROR-HANDLING, indirect-api=false, port=rpCS_SWCGateWay_TtToChime
        enable-take-address=true, error-handling=NO-TRANSFORMER-ERROR-HANDLING, indirect-api=false, port=rcCS_SWCNormal_ReceiveOffroadInfo
      15 x runnable:
        Common_GateWay_Init: can-enter-exclusive-area=ExclusiveArea
        Common_GateWay_5msMainFunction: can-enter-exclusive-area=ExclusiveArea
          data-read-access:
            5 x access:
              READ_rpSR_SWCGateWay_Power_Out_SystemStateOut: accessed-variable=rpSR_SWCGateWay_Power_Out.SystemStateOut
              READ_rpSR_SWCGateWay_Fuel_Set_Module_Data_Element: accessed-variable=rpSR_SWCGateWay_Fuel_Set_Module_Data.Element
              READ_rpSR_SWCGateWay_TC_Module_Output_Data_Element: accessed-variable=rpSR_SWCGateWay_TC_Module_Output_Data.Element
              REC_rpSR_SWCGateWay_ReceiveRTCTime_UtcTime: accessed-variable=rpSR_SWCGateWay_ReceiveRTCTime.UtcTime
              REC_rpSR_SWCGateWay_ReceiveRTCTime_SleepDateTime: accessed-variable=rpSR_SWCGateWay_ReceiveRTCTime.SleepDateTime
          data-receive-point-by-arguments:
            145 x access:
              REC_ABS3_0x265_ABS3_0x265: accessed-variable=ABS3_0x265.ABS3_0x265
              REC_BMS19_0x352_BMS19_0x352: accessed-variable=BMS19_0x352.BMS19_0x352
              REC_ECM1_0x111_ECM1_0x111: accessed-variable=ECM1_0x111.ECM1_0x111
              REC_ECM3_0x371_ECM3_0x371: accessed-variable=ECM3_0x371.ECM3_0x371
              REC_ESP2_0x145_ESP2_0x145: accessed-variable=ESP2_0x145.ESP2_0x145
              REC_ESP_FD2_0x137_ESP_FD2_0x137: accessed-variable=ESP_FD2_0x137.ESP_FD2_0x137
              REC_HCU_PT5_0x330_HCU_PT5_0x330: accessed-variable=HCU_PT5_0x14A.HCU_PT5_0x14A
              REC_AC1_0x29D_AC1_0x29D: accessed-variable=AC1_0x29D.AC1_0x29D
              REC_AC2_0x385_AC2_0x385: accessed-variable=AC2_0x385.AC2_0x385
              REC_ACC_FD2_0x2AB_ACC_FD2_0x2AB: accessed-variable=ACC_FD2_0x2AB.ACC_FD2_0x2AB
              REC_AEB_FD2_0x227_AEB_FD2_0x227: accessed-variable=AEB_FD2_0x227.AEB_FD2_0x227
              REC_BCM1_0x319_BCM1_0x319: accessed-variable=BCM1_0x319.BCM1_0x319
              REC_BCM3_0x345_BCM3_0x345: accessed-variable=BCM3_0x345.BCM3_0x345
              REC_BCM8_0x29F_BCM8_0x29F: accessed-variable=BCM8_0x29F.BCM8_0x29F
              REC_BMS30_0x3F1_BMS30_0x3F1: accessed-variable=BMS30_0x3F1.BMS30_0x3F1
              REC_BMS35_0x2C4_BMS35_0x2C4: accessed-variable=BMS35_0x2C4.BMS35_0x2C4
              REC_CP1_0x35E_CP1_0x35E: accessed-variable=CP1_0x35E.CP1_0x35E
              REC_CSA1_0x165_CSA1_0x165: accessed-variable=CSA1_0x165.CSA1_0x165
              REC_CSA2_0xA1_CSA2_0xA1: accessed-variable=CSA2_0xA1.CSA2_0xA1
              REC_CSA3_0x244_CSA3_0x244: accessed-variable=CSA3_0x244.CSA3_0x244
              REC_DCT5_0x221_DCT5_0x221: accessed-variable=DCT5_0x221.DCT5_0x221
              REC_DCT7_0x235_DCT7_0x235: accessed-variable=DCT7_0x235.DCT7_0x235
              REC_DDCM1_0x2CA_DDCM1_0x2CA: accessed-variable=DDCM1_0x2CA.DDCM1_0x2CA
              REC_DHT_FD1_0xC1_DHT_FD1_0xC1: accessed-variable=DHT_FD1_0xC1.DHT_FD1_0xC1
              REC_DMS_FD1_0x24D_DMS_FD1_0x24D: accessed-variable=DMS_FD1_0x24D.DMS_FD1_0x24D
              REC_ECM2_0x271_ECM2_0x271: accessed-variable=ECM2_0x271.ECM2_0x271
              REC_ECM_PT7_0x117_ECM_PT7_0x117: accessed-variable=ECM_PT7_0x117.ECM_PT7_0x117
              REC_EEM1_0x2A8_EEM1_0x2A8: accessed-variable=EEM1_0x2A8.EEM1_0x2A8
              REC_ELD1_0x152_ELD1_0x152: accessed-variable=ELD1_0x152.ELD1_0x152
              REC_EPB1_0x16B_EPB1_0x16B: accessed-variable=EPB1_0x16B.EPB1_0x16B
              REC_EPS1_0x168_EPS1_0x168: accessed-variable=EPS1_0x168.EPS1_0x168
              REC_EPS_FD1_0x147_EPS_FD1_0x147: accessed-variable=EPS_FD1_0x147.EPS_FD1_0x147
              REC_ESP10_0xD8_ESP10_0xD8: accessed-variable=ESP10_0xD8.ESP10_0xD8
              REC_ESP11_0xC8_ESP11_0xC8: accessed-variable=ESP11_0xC8.ESP11_0xC8
              REC_ESP1_0x149_ESP1_0x149: accessed-variable=ESP1_0x149.ESP1_0x149
              REC_ESP8_0x170_ESP8_0x170: accessed-variable=ESP8_0x170.ESP8_0x170
              REC_FPAS1_0x26D_FPAS1_0x26D: accessed-variable=FPAS1_0x26D.FPAS1_0x26D
              REC_F_PBox1_0x19B_F_PBox1_0x19B: accessed-variable=F_PBox1_0x19B.F_PBox1_0x19B
              REC_HAP_FD1_0x15B_HAP_FD1_0x15B: accessed-variable=HAP_FD1_0x15B.HAP_FD1_0x15B
              REC_Haldex1_0x251_Haldex1_0x251: accessed-variable=Haldex1_0x251.Haldex1_0x251
              REC_HAP_FD2_0x274_HAP_FD2_0x274: accessed-variable=HAP_FD2_0x274.HAP_FD2_0x274
              REC_HAP_FD3_0x298_HAP_FD3_0x298: accessed-variable=HAP_FD3_0x298.HAP_FD3_0x298
              REC_HC1_0x287_HC1_0x287: accessed-variable=HC1_0x287.HC1_0x287
              REC_HCU_HC6_0x314_HCU_HC6_0x314: accessed-variable=HCU_HC6_0x314.HCU_HC6_0x314
              REC_HCU_HC7_0x3C2_HCU_HC7_0x3C2: accessed-variable=HCU_HC7_0x3C2.HCU_HC7_0x3C2
              REC_HCU_PT4_0x2FA_HCU_PT4_0x2FA: accessed-variable=HCU_PT4_0x2FA.HCU_PT4_0x2FA
              REC_HCU_PT7_0x248_HCU_PT7_0x248: accessed-variable=HCU_PT7_0x248.HCU_PT7_0x248
              REC_HCU_PT8_0x1C0_HCU_PT8_0x1C0: accessed-variable=HCU_PT8_0x1C0.HCU_PT8_0x1C0
              REC_HUD1_0x325_HUD1_0x325: accessed-variable=HUD1_0x325.HUD1_0x325
              REC_IFC_FD3_0x2CF_IFC_FD3_0x2CF: accessed-variable=IFC_FD3_0x2CF.IFC_FD3_0x2CF
              REC_OBC1_0x316_OBC1_0x316: accessed-variable=OBC1_0x316.OBC1_0x316
              REC_OBC2_0x317_OBC2_0x317: accessed-variable=OBC2_0x317.OBC2_0x317
              REC_PDCM1_0x2CD_PDCM1_0x2CD: accessed-variable=PDCM1_0x2CD.PDCM1_0x2CD
              REC_PEPS2_0x295_PEPS2_0x295: accessed-variable=PEPS2_0x295.PEPS2_0x295
              REC_PEPS4_0x302_PEPS4_0x302: accessed-variable=PEPS4_0x302.PEPS4_0x302
              REC_RPAS1_0x26E_RPAS1_0x26E: accessed-variable=RPAS1_0x26E.RPAS1_0x26E
              REC_R_PBox1_0x19C_R_PBox1_0x19C: accessed-variable=R_PBox1_0x19C.R_PBox1_0x19C
              REC_RSDS_FD1_0x16F_RSDS_FD1_0x16F: accessed-variable=RSDS_FD1_0x16F.RSDS_FD1_0x16F
              REC_SCM1_0x2D1_SCM1_0x2D1: accessed-variable=SCM1_0x2D1.SCM1_0x2D1
              REC_TPMS1_0x341_TPMS1_0x341: accessed-variable=TPMS1_0x341.TPMS1_0x341
              REC_TPMS2_0x395_TPMS2_0x395: accessed-variable=TPMS2_0x395.TPMS2_0x395
              REC_T_Box_FD1_0x33_T_Box_FD1_0x33: accessed-variable=T_Box_FD1_0x33.T_Box_FD1_0x33
              REC_T_Box_FD3_0x3E9_T_Box_FD3_0x3E9: accessed-variable=T_Box_FD3_0x3E9.T_Box_FD3_0x3E9
              REC_Trailer1_0x273_Trailer1_0x273: accessed-variable=Trailer1_0x273.Trailer1_0x273
              REC_VSG1_0x2E1_VSG1_0x2E1: accessed-variable=VSG1_0x2E1.VSG1_0x2E1
              REC_WPC1_0x2BA_WPC1_0x2BA: accessed-variable=WPC1_0x2BA.WPC1_0x2BA
              REC_ESCL2_0x303_ESCL2_0x303: accessed-variable=ESCL2_0x303.ESCL2_0x303
              REC_BMS4_0xF1_BMS4_0xF1: accessed-variable=BMS4_0xF1.BMS4_0xF1
              REC_ABM1_0x351_ABM1_0x351: accessed-variable=ABM1_0x351.ABM1_0x351
              REC_IFC_FD2_0x23D_IFC_FD2_0x23D: accessed-variable=IFC_FD2_0x23D.IFC_FD2_0x23D
              REC_IFC_FD5_0x19F_IFC_FD5_0x19F: accessed-variable=IFC_FD5_0x19F.IFC_FD5_0x19F
              REC_IFC_FD6_0x222_IFC_FD6_0x222: accessed-variable=IFC_FD6_0x222.IFC_FD6_0x222
              REC_CR_FD1_0x15E_CR_FD1_0x15E: accessed-variable=CR_FD1_0x15E.CR_FD1_0x15E
              REC_EOL_PartNumber_0xF187_PartNumber_0xF187: accessed-variable=EOL_PartNumber_0xF187.PartNumber_0xF187
              REC_EOL_ReadHardVersion_0xF193_ReadHardVersion_0xF193: accessed-variable=EOL_ReadHardVersion_0xF193.ReadHardVersion_0xF193
              REC_EOL_ReadSerialNumber_ProductData_0xF18C_ReadSerialNumber_ProductData_0xF18C: accessed-variable=EOL_ReadSerialNumber_ProductData_0xF18C.ReadSerialNumber_ProductData_0xF18C
              REC_EOL_VIPSoftwareVersion_0xFD01_VIPSoftwareVersion_0xFD01: accessed-variable=EOL_VIPSoftwareVersion_0xFD01.VIPSoftwareVersion_0xFD01
              REC_AMP2_0x3E3_AMP2_0x3E3: accessed-variable=AMP2_0x3E3.AMP2_0x3E3
              REC_AMP3_0x3E5_AMP3_0x3E5: accessed-variable=AMP3_0x3E5.AMP3_0x3E5
              REC_BCM12_0x238_BCM12_0x238: accessed-variable=BCM12_0x238.BCM12_0x238
              REC_DSM1_0x2C1_DSM1_0x2C1: accessed-variable=DSM1_0x2C1.DSM1_0x2C1
              REC_GW_FD1_0x2BB_GW_FD1_0x2BB: accessed-variable=GW_FD1_0x2BB.GW_FD1_0x2BB
              REC_RPAS2_0x2ED_RPAS2_0x2ED: accessed-variable=RPAS2_0x2ED.RPAS2_0x2ED
              REC_RSDS_FD2_0x30A_RSDS_FD2_0x30A: accessed-variable=RSDS_FD2_0x30A.RSDS_FD2_0x30A
              REC_TMCU_FD3_0x3C9_TMCU_FD3_0x3C9: accessed-variable=TMCU_FD3_0x3C9.TMCU_FD3_0x3C9
              REC_ECM19_0x3B5_ECM_VIN: accessed-variable=ECM19_0x3B5.ECM19_0x3B5
              REC_RCCanOutputViaGateway_CheckSum_IP2: accessed-variable=Rc_CanOutputViaGateway.CheckSum_IP2
              REC_RCCanOutputViaGateway_IP_ABMWarnLmpFailrSts: accessed-variable=Rc_CanOutputViaGateway.IP_ABMWarnLmpFailrSts
              REC_RCCanOutputViaGateway_IP_ACCErr: accessed-variable=Rc_CanOutputViaGateway.IP_ACCErr
              REC_RCCanOutputViaGateway_IP_BattChrgLmpSts: accessed-variable=Rc_CanOutputViaGateway.IP_BattChrgLmpSts
              REC_RCCanOutputViaGateway_IP_DrvSeatBeltWarnLmpFailSts: accessed-variable=Rc_CanOutputViaGateway.IP_DrvSeatBeltWarnLmpFailSts
              REC_RCCanOutputViaGateway_IP_EngOilPressLowLmpSts: accessed-variable=Rc_CanOutputViaGateway.IP_EngOilPressLowLmpSts
              REC_RCCanOutputViaGateway_IP_Err: accessed-variable=Rc_CanOutputViaGateway.IP_Err
              REC_RCCanOutputViaGateway_IP_FuelLvlInfo: accessed-variable=Rc_CanOutputViaGateway.IP_FuelLvlInfo
              REC_RCCanOutputViaGateway_IP_FuelLvlLowLmpSts: accessed-variable=Rc_CanOutputViaGateway.IP_FuelLvlLowLmpSts
              REC_RCCanOutputViaGateway_IP_PassSeatBeltWarnLmpFailSts: accessed-variable=Rc_CanOutputViaGateway.IP_PassSeatBeltWarnLmpFailSts
              REC_RCCanOutputViaGateway_IP_VINcompr: accessed-variable=Rc_CanOutputViaGateway.IP_VINcompr
              REC_RCCanOutputViaGateway_IP_VehSpdUnit: accessed-variable=Rc_CanOutputViaGateway.IP_VehSpdUnit
              REC_RCCanOutputViaGateway_IP_VehTotDistance: accessed-variable=Rc_CanOutputViaGateway.IP_VehTotDistance
              REC_RCCanOutputViaGateway_IP_VehTotDistanceValid: accessed-variable=Rc_CanOutputViaGateway.IP_VehTotDistanceValid
              REC_RCCanOutputViaGateway_RollingCounter_IP2: accessed-variable=Rc_CanOutputViaGateway.RollingCounter_IP2
              REC_RCCanOutputViaGateway_dummy_HUT_IP2_0: accessed-variable=Rc_CanOutputViaGateway.dummy_HUT_IP2_0
              REC_Rc_CanOutputViaGateway_IP_AvgFuelCons: accessed-variable=Rc_CanOutputViaGateway.IP_AvgFuelCons
              REC_Rc_CanOutputViaGateway_IP_CurrTheme: accessed-variable=Rc_CanOutputViaGateway.IP_CurrTheme
              REC_Rc_CanOutputViaGateway_IP_FuelAuxTankR: accessed-variable=Rc_CanOutputViaGateway.IP_FuelAuxTankR
              REC_Rc_CanOutputViaGateway_IP_FuelMainTankR: accessed-variable=Rc_CanOutputViaGateway.IP_FuelMainTankR
              REC_Rc_CanOutputViaGateway_IP_InstFuelCons: accessed-variable=Rc_CanOutputViaGateway.IP_InstFuelCons
              REC_Rc_CanOutputViaGateway_IP_InstFuelConsUnit: accessed-variable=Rc_CanOutputViaGateway.IP_InstFuelConsUnit
              REC_Rc_CanOutputViaGateway_IP_LagueSet: accessed-variable=Rc_CanOutputViaGateway.IP_LagueSet
              REC_Rc_CanOutputViaGateway_IP_RemainDistance: accessed-variable=Rc_CanOutputViaGateway.IP_RemainDistance
              REC_Rc_CanOutputViaGateway_IP_VehSpdDisp: accessed-variable=Rc_CanOutputViaGateway.IP_VehSpdDisp
              REC_Rc_CanOutputViaGateway_IP_VelSpdDisp_Mile: accessed-variable=Rc_CanOutputViaGateway.IP_VelSpdDisp_Mile
              REC_ABS1_0x231_ABS1_0x231: accessed-variable=ABS1_0x231.ABS1_0x231
              REC_ABS2_0x246_ABS2_0x246: accessed-variable=ABS2_0x246.ABS2_0x246
              REC_ACC_FD3_0x2B4_ACC_FD3_0x2B4: accessed-variable=ACC_FD3_0x2B4.ACC_FD3_0x2B4
              REC_BCM6_0x28C_BCM6_0x28C: accessed-variable=BCM6_0x28C.BCM6_0x28C
              REC_PLG_1_0x2FE_PLG_1_0x2FE: accessed-variable=PLG_1_0x2FE.PLG_1_0x2FE
              REC_rpSR_SWCGateWay_DtcInfoForIPErrorStatus_Element: accessed-variable=rpSR_SWCGateWay_DtcInfoForIPErrorStatus.Element
              REC_IP_EBDFailSts_IP_EBDFailSts: accessed-variable=Rc_CanOutout_IP_EBDFailSts.IP_EBDFailSts
              REC_Rc_CanOutputViaGateway_IP_EBDFailSts: accessed-variable=Rc_CanOutputViaGateway.IP_EBDFailSts
              REC_SG_ACC7_ACC_FD2_SG_ACC7_ACC_FD2: accessed-variable=SG_ACC7_ACC_FD2.SG_ACC7_ACC_FD2
              REC_Cconfig_KindBuffers_400Bytes_CconfigKind_400Bytes: accessed-variable=Cconfig_KindBuffers_400Bytes.CconfigKind_400Bytes
              REC_DCT3_0xA6_DCT3_0xA6: accessed-variable=DCT3_0xA6.DCT3_0xA6
              REC_ECM11_0x2D3_ECM11_0x2D3: accessed-variable=ECM11_0x2D3.ECM11_0x2D3
              REC_rpSR_SWCGateWay_MenuSetData_Element: accessed-variable=rpSR_SWCGateWay_MenuSetData.Element
              REC_ACC_FD4_0x2B8_ACC_FD4_0x2B8: accessed-variable=ACC_FD4_0x2B8.ACC_FD4_0x2B8
              REC_SG_ACC6_ACC_FD2_SG_ACC6_ACC_FD2: accessed-variable=SG_ACC6_ACC_FD2.SG_ACC6_ACC_FD2
              REC_SG_ACC8_ACC_FD2_SG_ACC8_ACC_FD2: accessed-variable=SG_ACC8_ACC_FD2.SG_ACC8_ACC_FD2
              REC_SG_ACC3_ACC_FD2_SG_ACC3_ACC_FD2: accessed-variable=SG_ACC3_ACC_FD2.SG_ACC3_ACC_FD2
              REC_SG_ACC4_ACC_FD2_SG_ACC4_ACC_FD2: accessed-variable=SG_ACC4_ACC_FD2.SG_ACC4_ACC_FD2
              REC_piSR_E2ESwitchChangeTrigger_Element: accessed-variable=piSR_E2ESwitchChangeTrigger.Element
              REC_HAP_FD6_0x289_HAP_FD6_0x289: accessed-variable=HAP_FD6_0x289.HAP_FD6_0x289
              REC_HAP_FD7_0x29B_HAP_FD7_0x29B: accessed-variable=HAP_FD7_0x29B.HAP_FD7_0x29B
              REC_HCM_L1_0x308_HCM_L1_0x308: accessed-variable=HCM_L1_0x308.HCM_L1_0x308
              REC_HCM_R1_0x30D_HCM_R1_0x30D: accessed-variable=HCM_R1_0x30D.HCM_R1_0x30D
              REC_BMS22_0x3BF_BMS22_0x3BF: accessed-variable=BMS22_0x3BF.BMS22_0x3BF
              REC_BMS8_0x285_BMS8_0x285: accessed-variable=BMS8_0x285.BMS8_0x285
              REC_BMS_FD14_0x1E3_BMS_FD14_0x1E3: accessed-variable=BMS_FD14_0x1E3.BMS_FD14_0x1E3
              REC_HCU_FD1_0x60_HCU_FD1_0x60: accessed-variable=HCU_FD1_0x60.HCU_FD1_0x60
              REC_HCU_HC3_0x268_HCU_HC3_0x268: accessed-variable=HCU_HC3_0x268.HCU_HC3_0x268
              REC_HCU_HC8_0x1E2_HCU_HC8_0x1E2: accessed-variable=HCU_HC8_0x1E2.HCU_HC8_0x1E2
              REC_HCU_HP5_0x201_HCU_HP5_0x201: accessed-variable=HCU_HP5_0x201.HCU_HP5_0x201
              REC_HCU_HP6_0x11A_HCU_HP6_0x11A: accessed-variable=HCU_HP6_0x11A.HCU_HP6_0x11A
              REC_Vconfig_GetKindBuffers_Kind600Bytes: accessed-variable=Vconfig_GetKindBuffers.AllKinds
              REC_rpSR_SWCGateWay_CanOutput_IP_ABMWarnLmpFailrSts_Element: accessed-variable=rpSR_SWCGateWay_CanOutput_IP_ABMWarnLmpFailrSts.Element
          data-send-points:
            47 x access:
              SEND_HUT1_0x367_HUT1_0x367: accessed-variable=HUT1_0x367.HUT1_0x367
              SEND_HUT10_0x331_HUT10_0x331: accessed-variable=HUT10_0x331.HUT10_0x331
              SEND_HUT17_0x33B_HUT17_0x33B: accessed-variable=HUT17_0x33B.HUT17_0x33B
              SEND_HUT25_0x339_HUT25_0x339: accessed-variable=HUT25_0x339.HUT25_0x339
              SEND_HUT2_0x369_HUT2_0x369: accessed-variable=HUT2_0x369.HUT2_0x369
              SEND_HUT33_0x1ED_HUT33_0x1ED: accessed-variable=HUT33_0x1ED.HUT33_0x1ED
              SEND_HUT4_0x36D_HUT4_0x36D: accessed-variable=HUT4_0x36D.HUT4_0x36D
              SEND_HUT_IP2_0x27F_HUT_IP2_0x27F: accessed-variable=HUT_IP2_0x27F.HUT_IP2_0x27F
              SEND_HUT32_0x26F_HUT32_0x26F: accessed-variable=HUT32_0x26F.HUT32_0x26F
              SEND_HUT13_0x31C_HUT13_0x31C: accessed-variable=HUT13_0x31C.HUT13_0x31C
              SEND_HUT15_0x1EE_HUT15_0x1EE: accessed-variable=HUT15_0x1EE.HUT15_0x1EE
              SEND_HUT19_0x415_HUT19_0x415: accessed-variable=HUT19_0x415.HUT19_0x415
              SEND_HUT20_0x2DE_HUT20_0x2DE: accessed-variable=HUT20_0x2DE.HUT20_0x2DE
              SEND_HUT21_0x2DD_HUT21_0x2DD: accessed-variable=HUT21_0x2DD.HUT21_0x2DD
              SEND_HUT22_0x2DA_HUT22_0x2DA: accessed-variable=HUT22_0x2DA.HUT22_0x2DA
              SEND_HUT23_0x2D8_HUT23_0x2D8: accessed-variable=HUT23_0x2D8.HUT23_0x2D8
              SEND_HUT26_0x2B6_HUT26_0x2B6: accessed-variable=HUT26_0x2B6.HUT26_0x2B6
              SEND_HUT30_0x1E9_HUT30_0x1E9: accessed-variable=HUT30_0x1E9.HUT30_0x1E9
              SEND_HUT39_0x1EB_HUT39_0x1EB: accessed-variable=HUT39_0x1EB.HUT39_0x1EB
              SEND_HUT6_0x4A_HUT6_0x4A: accessed-variable=HUT6_0x4A.HUT6_0x4A
              SEND_HUT_FD1_0x2C3_HUT_FD1_0x2C3: accessed-variable=HUT_FD1_0x2C3.HUT_FD1_0x2C3
              SEND_SocReadyFlag_Element: accessed-variable=SocReadyFlag.Element
              SEND_IP_LagueSet_IP_LagueSet: accessed-variable=IP_LagueSet.IP_LagueSet
              SEND_IP_VehSpdDisp_IP_VehSpdDisp: accessed-variable=IP_VehSpdDisp.IP_VehSpdDisp
              SEND_IP_VelSpdDisp_Mile_IP_VelSpdDisp_Mile: accessed-variable=IP_VelSpdDisp_Mile.IP_VelSpdDisp_Mile
              SEND_IP_FuelAuxTankR_IP_FuelAuxTankR: accessed-variable=IP_FuelAuxTankR.IP_FuelAuxTankR
              SEND_IP_FuelMainTankR_IP_FuelMainTankR: accessed-variable=IP_FuelMainTankR.IP_FuelMainTankR
              SEND_IP_CurrTheme_IP_CurrTheme: accessed-variable=IP_CurrTheme.IP_CurrTheme
              SEND_IP_InstFuelCons_IP_InstFuelCons: accessed-variable=IP_InstFuelCons.IP_InstFuelCons
              SEND_IP_AvgFuelCons_IP_AvgFuelCons: accessed-variable=IP_AvgFuelCons.IP_AvgFuelCons
              SEND_IP_InstFuelConsUnit_IP_InstFuelConsUnit: accessed-variable=IP_InstFuelConsUnit.IP_InstFuelConsUnit
              SEND_IP_RemainDistance_IP_RemainDistance: accessed-variable=IP_RemainDistance.IP_RemainDistance
              SEND_HUT16_0x348_HUT16_0x348: accessed-variable=HUT16_0x348.HUT16_0x348
              SEND_HUT3_0x36B_HUT3_0x36B: accessed-variable=HUT3_0x36B.HUT3_0x36B
              SEND_HUT34_0x370_HUT34_0x370: accessed-variable=HUT34_0x370.HUT34_0x370
              SEND_SG_HUT_IP2_SG_HUT_IP2: accessed-variable=SG_HUT_IP2.SG_HUT_IP2
              SEND_HUT_IP1_0x293_HUT_IP1_0x293: accessed-variable=HUT_IP1_0x293.HUT_IP1_0x293
              SEND_HUT_IP3_0x34A_HUT_IP3_0x34A: accessed-variable=HUT_IP3_0x34A.HUT_IP3_0x34A
              SEND_SG_HUT32_SG_HUT32: accessed-variable=SG_HUT32.SG_HUT32
              SEND_ppSR_SWCGateWay_S2M_Information_SpeedValue: accessed-variable=ppSR_SWCGateWay_S2M_Information.SpeedValue
              SEND_ppSR_SWCGateWay_S2M_Information_TachoValue: accessed-variable=ppSR_SWCGateWay_S2M_Information.TachoValue
              SEND_HUT35_0x1E5_HUT35_0x1E5: accessed-variable=HUT35_0x1E5.HUT35_0x1E5
              SEND_HUT_FD4_0x1DA_HUT_FD4_0x1DA: accessed-variable=HUT_FD4_0x1DA.HUT_FD4_0x1DA
              SEND_HUT40_0x2CE_HUT40_0x2CE: accessed-variable=HUT40_0x2CE.HUT40_0x2CE
              SEND_ppSR_SWCGateWay_EnergyInfoId_Data: accessed-variable=ppSR_SWCGateWay_EnergyInfoId.Data
              SEND_AWakeHold_DVRRemtCnSts: accessed-variable=AWakeHold.DVRRemtCnSts
              SEND_AwakeHlod_Heartbeat_counter: accessed-variable=AwakeHlod_Heartbeat.counter
          52 x sync call:
            SC_NvMService_AC3_Defs_NvBlockNeed_Block_IPC_CAN_Data_EraseBlock: operation=NvMService_AC3_Defs_NvBlockNeed_Block_IPC_CAN_Data.EraseBlock
            SC_NvMService_AC3_Defs_NvBlockNeed_Block_IPC_CAN_Data_GetErrorStatus: operation=NvMService_AC3_Defs_NvBlockNeed_Block_IPC_CAN_Data.GetErrorStatus
            SC_NvMService_AC3_Defs_NvBlockNeed_Block_IPC_CAN_Data_InvalidateNvBlock: operation=NvMService_AC3_Defs_NvBlockNeed_Block_IPC_CAN_Data.InvalidateNvBlock
            SC_NvMService_AC3_Defs_NvBlockNeed_Block_IPC_CAN_Data_ReadBlock: operation=NvMService_AC3_Defs_NvBlockNeed_Block_IPC_CAN_Data.ReadBlock
            SC_NvMService_AC3_Defs_NvBlockNeed_Block_IPC_CAN_Data_RestoreBlockDefaults: operation=NvMService_AC3_Defs_NvBlockNeed_Block_IPC_CAN_Data.RestoreBlockDefaults
            SC_NvMService_AC3_Defs_NvBlockNeed_Block_IPC_CAN_Data_WriteBlock: operation=NvMService_AC3_Defs_NvBlockNeed_Block_IPC_CAN_Data.WriteBlock
            SC_NvMService_AC3_Defs_NvBlockNeed_Block_IPC_Config_Data_EraseBlock: operation=NvMService_AC3_Defs_NvBlockNeed_Block_IPC_Config_Data.EraseBlock
            SC_NvMService_AC3_Defs_NvBlockNeed_Block_IPC_Config_Data_GetErrorStatus: operation=NvMService_AC3_Defs_NvBlockNeed_Block_IPC_Config_Data.GetErrorStatus
            SC_NvMService_AC3_Defs_NvBlockNeed_Block_IPC_Config_Data_InvalidateNvBlock: operation=NvMService_AC3_Defs_NvBlockNeed_Block_IPC_Config_Data.InvalidateNvBlock
            SC_NvMService_AC3_Defs_NvBlockNeed_Block_IPC_Config_Data_ReadBlock: operation=NvMService_AC3_Defs_NvBlockNeed_Block_IPC_Config_Data.ReadBlock
            SC_NvMService_AC3_Defs_NvBlockNeed_Block_IPC_Config_Data_RestoreBlockDefaults: operation=NvMService_AC3_Defs_NvBlockNeed_Block_IPC_Config_Data.RestoreBlockDefaults
            SC_NvMService_AC3_Defs_NvBlockNeed_Block_IPC_Config_Data_WriteBlock: operation=NvMService_AC3_Defs_NvBlockNeed_Block_IPC_Config_Data.WriteBlock
            SC_rcCS_SWCNormal_ChimeCallback_Operation: operation=rcCS_SWCNormal_ChimeCallback.Operation
            SC_rcCS_SWCNormal_TTCallback_Operation: operation=rcCS_SWCNormal_TTCallback.Operation
            SC_rcCS_SWCNormal_WrnCallback_Operation: operation=rcCS_SWCNormal_WrnCallback.Operation
            SC_rpCS_AppClearDTCInfo_AppClearDTCInfo: operation=rpCS_AppClearDTCInfo.AppClearDTCInfo
            SC_rpCS_AppReadDtcInfomation_AppReadDtcInformation: operation=rpCS_AppReadDtcInfomation.AppReadDtcInformation
            SC_CNA_SignalSet_Operation: operation=CNA_SignalSet.Operation
            SC_rcCS_SWCNormal_HMIResetTC_Callback: operation=rcCS_SWCNormal_HMIResetTC.Callback
            SC_rcCS_SWCNormal_ReceiveMenuSetting_Callback: operation=rcCS_SWCNormal_ReceiveMenuSetting.Callback
            SC_rpCS_SWCGateWay_GetVinNumber_Operation: operation=rpCS_SWCGateWay_GetVinNumber.Operation
            SC_ComM_UserRequest_GetCurrentComMode: operation=ComM_UserRequest.GetCurrentComMode
            SC_ComM_UserRequest_GetMaxComMode: operation=ComM_UserRequest.GetMaxComMode
            SC_ComM_UserRequest_GetRequestedComMode: operation=ComM_UserRequest.GetRequestedComMode
            SC_ComM_UserRequest_RequestComMode: operation=ComM_UserRequest.RequestComMode
            SC_rpCS_SWCGateWay_ReceiveSafetyGearCRC_Callback: operation=rpCS_SWCGateWay_ReceiveSafetyGearCRC.Callback
            SC_rpCS_SWCGateWay_ReceiveSafetyTTCRC_Callback: operation=rpCS_SWCGateWay_ReceiveSafetyTTCRC.Callback
            SC_rcCS_SWCGateWay_ReceiveSafetyGearCRC_Callback: operation=rcCS_SWCGateWay_ReceiveSafetyGearCRC.Callback
            SC_rcCS_SWCGateWay_ReceiveSafetyTTCRC_Callback: operation=rcCS_SWCGateWay_ReceiveSafetyTTCRC.Callback
            SC_rpCS_GetCANMatrixVersionInfo_Data: operation=rpCS_GetCANMatrixVersionInfo.Data
            SC_rpCS_GetVehicleModeInfo_Data: operation=rpCS_GetVehicleModeInfo.Data
            SC_rpCS_SWCSafety_TTCallback_Operation: operation=rpCS_SWCSafety_TTCallback.Operation
            SC_IPC_DataSend_If_Operation: operation=IPC_DataSend_If.Operation
            SC_rpCS_SWCGateWay_E2ESwitchStatusRead_Operation: operation=rpCS_SWCGateWay_E2ESwitchStatusRead.Operation
            SC_rpCS_SWCGateWay_E2ESwitchStatusWrite_Operation: operation=rpCS_SWCGateWay_E2ESwitchStatusWrite.Operation
            SC_rpCS_SWCGateWay_SecOcSwitchStatusRead_Operation: operation=rpCS_SWCGateWay_SecOcSwitchStatusRead.Operation
            SC_rpCS_SWCGateWay_SecOcSwitchStatusWrite_Operation: operation=rpCS_SWCGateWay_SecOcSwitchStatusWrite.Operation
            SC_rpCS_SWCGateWay_TC_EnergyInfo_Operation: operation=rpCS_SWCGateWay_TC_EnergyInfo.Operation
            SC_rpCS_SWCGateWay_TC_EnergyInfoResp_Operation: operation=rpCS_SWCGateWay_TC_EnergyInfoResp.Operation
            SC_rpCS_SWCGateWay_ComEx_GetRxE2EStatus: operation=rpCS_SWCGateWay_ComEx.GetRxE2EStatus
            SC_rpCS_SWCGateWay_ComEx_ReceiveSignal: operation=rpCS_SWCGateWay_ComEx.ReceiveSignal
            SC_rpCS_SWCGateWay_ComEx_SendSignal: operation=rpCS_SWCGateWay_ComEx.SendSignal
            SC_rpCS_SWCGateWay_AdasStatus_Callback: operation=rpCS_SWCGateWay_AdasStatus.Callback
            SC_rpCS_SWCGateWay_ReceiveHMIPowerMode_Callback: operation=rpCS_SWCGateWay_ReceiveHMIPowerMode.Callback
            SC_rpCS_SWCGateway_UTCTime_UTC2PerpetualCalendar: operation=rpCS_SWCGateway_UTCTime.UTC2PerpetualCalendar
            SC_rpCS_SWCGateWay_CNA_SignalSetNoTrigger_Operation: operation=rpCS_SWCGateWay_CNA_SignalSetNoTrigger.Operation
            SC_rpCS_SWCGateWay_ReceiveMenuTheme_Callback: operation=rpCS_SWCGateWay_ReceiveMenuTheme.Callback
            SC_rpCS_SWCGateWay_CNA_SignalSet_U8N_Operation: operation=rpCS_SWCGateWay_CNA_SignalSet_U8N.Operation
            SC_rpCS_SWCGateWay_TtToChime_Callback: operation=rpCS_SWCGateWay_TtToChime.Callback
            SC_CNA_SignalGroupSet_Operation: operation=CNA_SignalGroupSet.Operation
            SC_VConfig_GetKindConfig_Operation_VConfig_GetKindConfig: operation=VConfig_GetKindConfig.Operation_VConfig_GetKindConfig
            SC_rcCS_SWCNormal_ReceiveOffroadInfo_Callback: operation=rcCS_SWCNormal_ReceiveOffroadInfo.Callback
        Common_GW_List_Deinit
        Common_GW_List_Int
        IPC_Send_IPC_Send: can-be-invoked-concurrently=true
        NvMNotifyJobFinished_NvBlockNeed_Block_IPC_Config_Data_JobFinished
        NvMNotifyJobFinished_NvBlockNeed_Block_IPC_CAN_Data_JobFinished
        ppCS_SWCNormal_Callback_Operation
        Common_GateWay_Standby2Nomal_Callbcak: can-be-invoked-concurrently=true
        Common_GateWay_Nomal2Standby_Callbcak: can-be-invoked-concurrently=true
        IPC_Tx_E2E_CanMsg_HUT_IP2_Callback
        IPC_TransmitSignal_Callback
        IPC_API_SetEventTxSignalBuffer_Operation
        IPC_Tx_E2E_CanMsg_HUT32_CallBack
        Common_GateWay_10msMainFunction
      swc service dependency NvBlockNeed_Block_IPC_Config_Data
        assigned-datas:
          role=ramBlock, used-data-element=NvBlockNeed_Block_IPC_Config_Data_MirrorBlock
          role=defaultValue, used-parameter-element=NvBlockNeed_Block_IPC_Config_Data_DefaultValue
        assigned-ports:
          port-prototype=NvMNotifyJobFinished_NvBlockNeed_Block_IPC_Config_Data, role=NvMNotifyJobFinished
          port-prototype=NvMService_AC3_Defs_NvBlockNeed_Block_IPC_Config_Data, role=NvMService_AC3_Defs
        service-needs:
          nv block needs NvBlockNeed: n-data-sets=0, ram-block-status-control=API, reliability=NO-PROTECTION, restore-at-start=true, store-at-shutdown=true
      swc service dependency NvBlockNeed_Block_IPC_CAN_Data
        assigned-datas:
          role=ramBlock, used-data-element=NvBlockNeed_Block_IPC_CAN_Data_MirrorBlock
          role=defaultValue, used-parameter-element=NvBlockNeed_Block_IPC_CAN_Data_DefaultValue
        assigned-ports:
          port-prototype=NvMNotifyJobFinished_NvBlockNeed_Block_IPC_CAN_Data, role=NvMNotifyJobFinished
          port-prototype=NvMService_AC3_Defs_NvBlockNeed_Block_IPC_CAN_Data, role=NvMService_AC3_Defs
        service-needs:
          nv block needs NvBlockNeed: n-data-sets=0, ram-block-status-control=API, reliability=NO-PROTECTION, restore-at-start=true, store-at-shutdown=true
      shared-parameters:
        parameter data prototype NvBlockNeed_Block_IPC_Config_Data_DefaultValue: sw-calibration-access=READ-WRITE, type=IPC_Config_Type, init-value=constant-reference=IPC_Config_Init
        parameter data prototype NvBlockNeed_Block_IPC_CAN_Data_DefaultValue: sw-calibration-access=READ-WRITE, type=NVM_IPC_CAN_Type, init-value=constant-reference=NVM_IPC_CAN_Init
